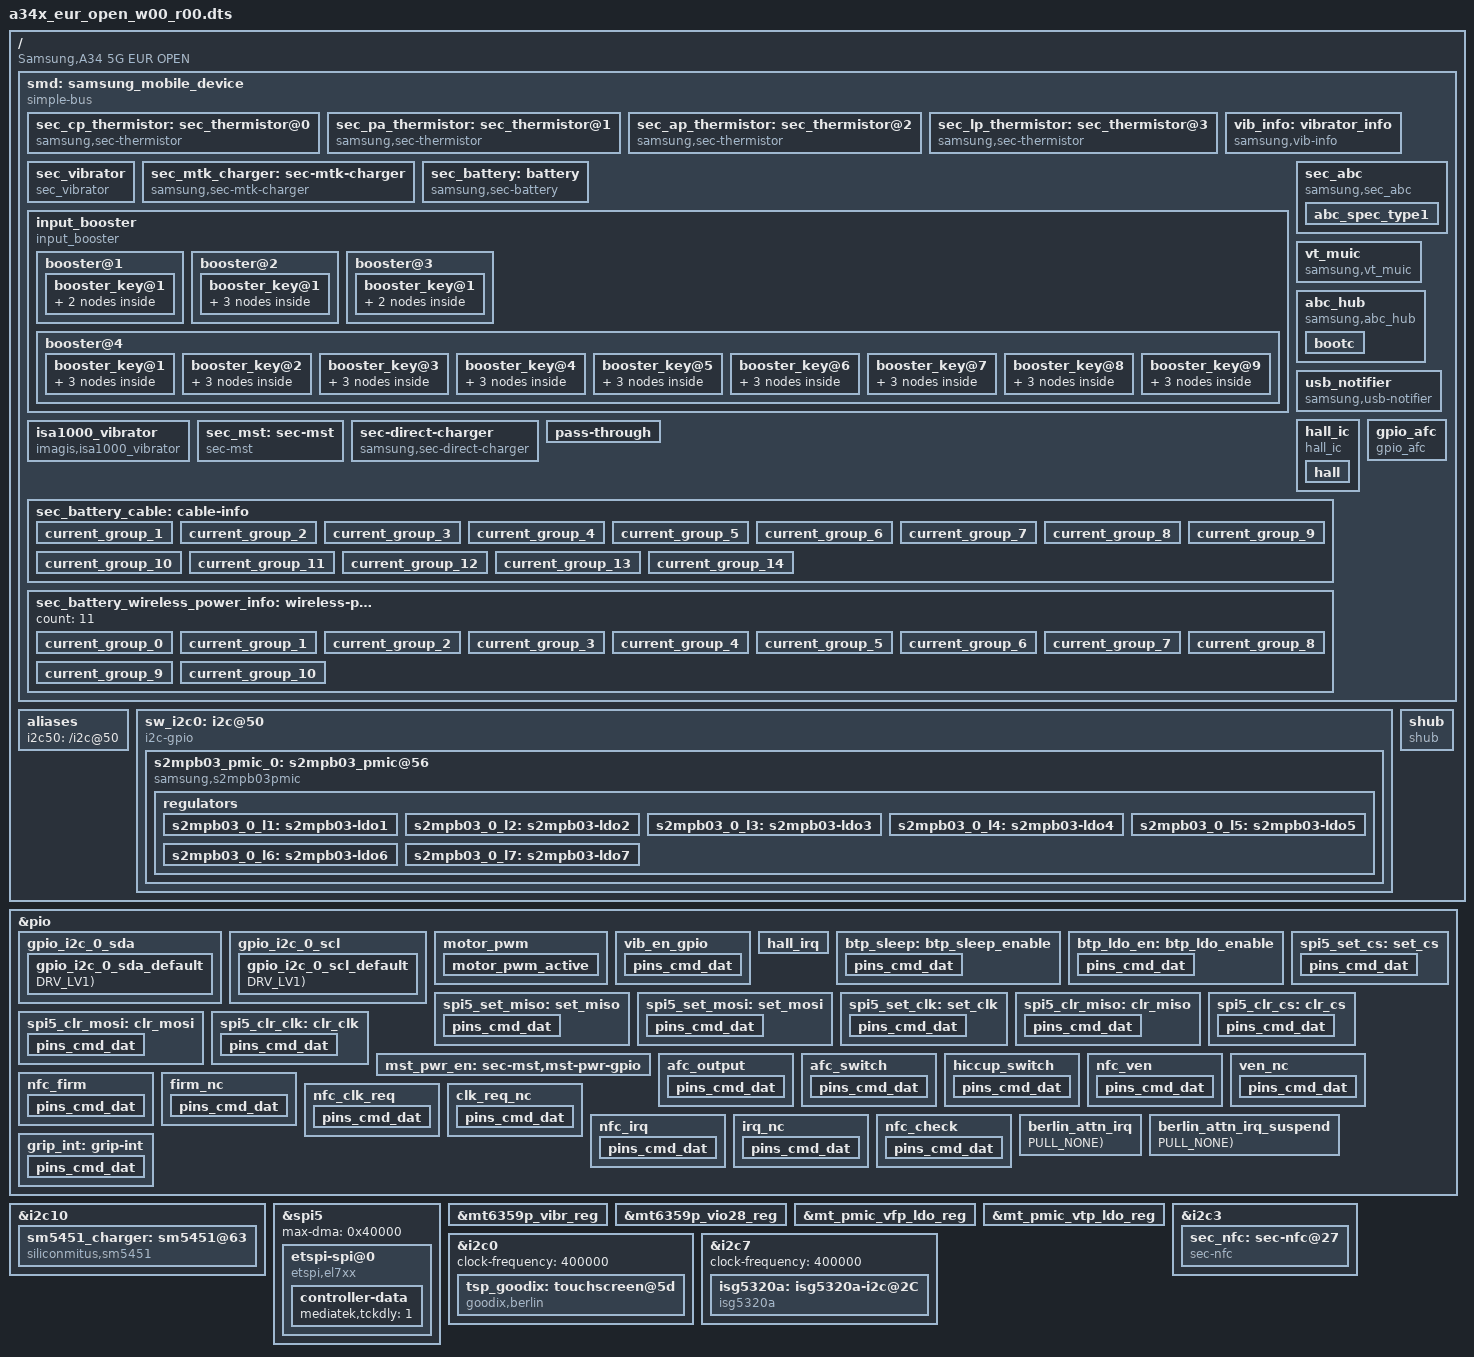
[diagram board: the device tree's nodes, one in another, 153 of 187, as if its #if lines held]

/*
 * Copyright (c) 2018 Samsung Electronics Co., Ltd.
 *              http://www.samsung.com
 *
 * This program is free software; you can redistribute it and/or modify
 * it under the terms of the GNU General Public License version 2 as
 * published by the Free Software Foundation.
*/

/dts-v1/;
/plugin/;
/ {
	fragment@smd {
		target-path = "/";
		__overlay__ {
			smd: samsung_mobile_device {
				compatible = "simple-bus";
			};
		};
	};
};

/* #include "../vibrator_vib_info.dtsi" */           /* From vibrator_vib_info.py */

&smd {
	vib_info: vibrator_info {
		status = "okay";
		compatible = "samsung,vib-info";
		functions = "INTENSITY", "HAPTIC_ENGINE";
#if 1
		samsung,intensities = <0 2000 4000 6000 8000 10000>;
#else
		samsung,intensities = <>;
#endif

#if 1
		samsung,haptic_intensities = <0 3000 4000 6000 8000 10000>;
#else
		samsung,haptic_intensities = <>;
#endif
	};
};

/* #include "../sec_vibrator.dtsi" */                /* From sec_vibrator.py */

&smd {
	sec_vibrator {
		status = "okay";
		compatible = "sec_vibrator";

		haptic,normal_ratio = <84>;
		haptic,high_temp_ref = <48>;
		haptic,high_temp_ratio = <71>;
	};
};


/* #include "../sec_mtk_charger.dtsi" */             /* From sec_mtk_charger.py */
#if 0
&${pogo_int_gpio_parent} {
	pogo_int_default: pogo_int_default {
		GPIO_CONFIG_PUD(${pogo_int_gpio}, FUNC_INPUT_WAKEUP, PULL_NONE);
	};
};
#endif

&smd {
	sec_mtk_charger: sec-mtk-charger {
#if 0
		pinctrl-names = "default";
		pinctrl-0 = <&pogo_int_default>;
		charger,pogo_int = <SEC_GPIO_REF(${pogo_int_gpio}) 0>; /* POGO_INT */
#endif
		compatible = "samsung,sec-mtk-charger";
		charger,vbus_min_charger_voltage = <4400000>;
		charger,vbus_normal_mivr_voltage = <4400000>;
		charger,gpio_chgenb = <&pio 184 0x0>;
		charger,max_icl = <3225>;
		charger,ib_fcc = <100>;
	};

	battery {
		battery,otg_name = "mtk-otg";
	};
};

/* /home/dpi/qb5_8814/workspace/P4_1716/android/kernel/kmodule/battery/suwon/charger/sec_mtk_charger/sec_mtk_charger.a34x.dtsi */

&smd {
	sec_mtk_charger: sec-mtk-charger {
		charger,gpio_chgenb = <&pio 27 0x0>;
		charger,mt6360_charger = <1>;
	};
};

/* #include "../nc.dtsi" */                          /* From nc.py */
#define LEGO_IS_USE_NC
#define LEGO_IS_USE(x, ...) !defined(LEGO_IS_USE_##x)

/* #include "../sec_pinctrl_wrapper.dtsi" */         /* From sec_pinctrl_wrapper.py */
#define PIN_FUNC_INPUT		input-enable
#define PIN_FUNC_INPUT_WAKEUP	input-enable
#define PIN_FUNC_OUTPUT		output-enable
#define PIN_FUNC_OUTPUT_HIGH		output-high
#define PIN_FUNC_OUTPUT_LOW		output-low

#define PIN_PULL_NONE	bias-disable
#define PIN_PULL_DOWN	bias-pull-down
#define PIN_PULL_UP	bias-pull-up
#define PIN_PULL_OPEN	bias-high-impedance

/*
 * MTK_DRIVE_2mA  2
 * MTK_DRIVE_4mA  4
 * MTK_DRIVE_6mA  6
 * MTK_DRIVE_8mA  8
 * MTK_DRIVE_10mA 10
 * MTK_DRIVE_12mA 12
 * MTK_DRIVE_14mA 14
 * MTK_DRIVE_16mA 16
 */

#define PIN_DRV_LV1	2
#define PIN_DRV_LV2	4
#define PIN_DRV_LV3	6
#define PIN_DRV_LV4	8
#define PIN_DRV_LV5	10
#define PIN_DRV_LV6	12
#define PIN_DRV_LV7	14
#define PIN_DRV_LV8	16

#define PIN_EXPAND(pin) #pin

#define SEC_GPIO(src, type, num)	PIN_EXPAND(gpio##num)
#define SEC_GPIO_REF(src, type, num)	&type num
#define SEC_GPIO_NUM(src, type, num)	num
#define SEC_GPIO_TYPE(src, type, num)	&type
#define SEC_GPIO_PHANDLE_ACTIVE(src, type, num)	SEC_GPIO_PHANDLE(type, num, active)
#define SEC_GPIO_PHANDLE_SLEEP(src, type, num)	SEC_GPIO_PHANDLE(type, num, sleep)
#define SEC_GPIO_PHANDLE(type, num, mode)	type##_##num##_##mode

#define MTK_PINMUX(gpio, func) (MTK_PIN_NO(gpio) | func)

#define GPIO_CONFIG(_src, _type, _num, _func)		\
	pins_cmd_dat{					\
		pinmux = <MTK_PINMUX(SEC_GPIO_NUM(_src, _type, _num), 0)>;	\
		PIN_ ##_func;		\
	}

#define GPIO_CONFIG_PUD(_src, _type, _num, _func, _pull)	\
	pins_cmd_dat{					\
		pinmux = <MTK_PINMUX(SEC_GPIO_NUM(_src, _type, _num), 0)>;	\
		PIN_ ##_pull;				\
		PIN_ ##_func;		\
	}

#define GPIO_CONFIG_PUD_DRV(_src, _type, _num, _func, _pull, _drv)	\
	pins_cmd_dat{					\
		pinmux = <MTK_PINMUX(SEC_GPIO_NUM(_src, _type, _num), 0)>;	\
		PIN_ ##_pull;				\
		PIN_ ##_func;		\
		drive-strength = <PIN_ ##_drv>;	\
	}

#define SEC_ADC(type, num) <&type num>
#define SEC_ADC_OPT(type, num) ,<&type num>
#define SEC_ADC_NUM(type, num) <num>

/* #include "../input_booster.dtsi" */               /* From input_booster.py */
/* Copyright (c) 2019, The Linux Foundation. All rights reserved.
 *
 * This program is free software; you can redistribute it and/or modify
 * it under the terms of the GNU General Public License version 2 and
 * only version 2 as published by the Free Software Foundation.
 *
 * This program is distributed in the hope that it will be useful,
 * but WITHOUT ANY WARRANTY; without even the implied warranty of
 * MERCHANTABILITY or FITNESS FOR A PARTICULAR PURPOSE.  See the
 * GNU General Public License for more details.
 */

&smd {
	input_booster {
		status = "okay";
		compatible = "input_booster";
		resValcount = "2";
		max_resource_count = "2";
		max_cluster_count = "3";
		#address-cells = <1>;
		#size-cells = <0>;

		/* Each Cpu Cluster Start Cpu */
		cpu_cluster_policy = "6,0";

		/* < CPU, DDR, SCHEDBOOST > */
		ib_release_values = "-1,16";

		/* Select Allowed Resource Index Group */
		allowed_resources = "0,1";

		booster@1 {
			booster,label = "Disable_Mode";
			booster,mode = "1";
			booster_key@1 {
				input_booster,label = "Touch_Disable";
				input_booster,type = <2>;	/* BOOSTER_DEVICE_TOUCH */
				/* Time table */
				input_booster,head_time = <0>;
				input_booster,tail_time = <0>;
				input_booster,resource {
					compatible = "resource";
					resource@1 {
						resource,label = "CPU";
						resource,id = "0";
						resource,value = <0 0>;
					};
				};
			};
		};

		booster@2 {
			booster,label = "Sip_Mode";
			booster,mode = "2";
			booster_key@1 {
				input_booster,label = "sip_touch";
				input_booster,type = <2>;	/* BOOSTER_DEVICE_TOUCH */
				/* Time table */
				input_booster,head_time = <120>;
				input_booster,tail_time = <0>;
				input_booster,resource {
					compatible = "resource";
					resource@1 {
						resource,label = "CPU";
						resource,id = "0";
						resource,value = <1140000 0>;
					};
					resource@2 {
						resource,label = "DDR";
						resource,id = "1";
						resource,value = <4266 4266>;
					};
				};
			};
		};

		booster@3 {
			booster,label = "Game_Mode";
			booster,mode = "3";
			booster_key@1 {
				input_booster,label = "GAME_MT";
				input_booster,type = <3>;	/* BOOSTER_DEVICE_MULTITOUCH */
				/* Time table */
				input_booster,head_time = <0>;
				input_booster,tail_time = <0>;
				input_booster,resource {
					compatible = "resource";
					resource@1 {
						resource,label = "CPU";
						resource,id = "0";
						resource,value = <0 0>;
					};
				};
			};
		};

		booster@4 {
			booster,label = "input_booster";
			booster,mode = "0";

			booster_key@1 {
				input_booster,label = "key";
				input_booster,type = <0>;	/* BOOSTER_DEVICE_KEY */

				/* Time table */
				input_booster,head_time = <200>;
				input_booster,tail_time = <0>;

				/* Resource Table Sequentially identified with index
				 * CPU's ID & Index : 0
				 * DDR's ID & Index : 1
				 * HMP's ID & Index : 2
				 * LPM's ID & Index : 3
				*/

				/* Input Booster Resource Frequency */
				inputbooster,resource {
					compatible = "resource";
					resource@1 {
						resource,label = "CPU";
						resource,id = "0";
						resource,value = <1540000 0>;
					};

					resource@2 {
						resource,label = "DDR";
						resource,id = "1";
						resource,value = <0 0>;
					};
				};
			};

			booster_key@2 {
				input_booster,label = "touchkey";
				input_booster,type = <1>;	/* BOOSTER_DEVICE_TOUCHKEY */

				/* Time table */
				input_booster,head_time = <1>;
				input_booster,tail_time = <300>;

				/* Input Booster Resource Frequency */
				inputbooster,resource {
					compatible = "resource";
					resource@1 {
						resource,label = "CPU";
						resource,id = "0";
						resource,value = <0 0>;
					};

					resource@2 {
						resource,label = "DDR";
						resource,id = "1";
						resource,value = <0 0>;
					};
				};
			};

			booster_key@3 {
				input_booster,label = "touch";
				input_booster,type = <2>;	/* BOOSTER_DEVICE_TOUCH */

				/* Time table */
				input_booster,head_time = <130>;
				input_booster,tail_time = <500>;

				/* Input Booster Resource Frequency */
				inputbooster,resource {
					compatible = "resource";
					resource@1 {
						resource,label = "CPU";
						resource,id = "0";
						resource,value = <1140000 1075200>;
					};

					resource@2 {
						resource,label = "DDR";
						resource,id = "1";
						resource,value = <4266 4266>;
					};
				};
			};

			booster_key@4 {
				input_booster,label = "multitouch";
				input_booster,type = <3>;	/* BOOSTER_DEVICE_MULTITOUCH */

				/* Time table */
				input_booster,head_time = <1000>;
				input_booster,tail_time = <500>;

				/* Input Booster Resource Frequency */
				inputbooster,resource {
					compatible = "resource";
					resource@1 {
						resource,label = "CPU";
						resource,id = "0";
						resource,value = <1140000 1075200>;
					};

					resource@2 {
						resource,label = "DDR";
						resource,id = "1";
						resource,value = <4266 4266>;
					};
				};
			};

			booster_key@5 {
				input_booster,label = "keyboard";
				input_booster,type = <4>;	/* BOOSTER_DEVICE_KEYBOARD */

				/* Time table */
				input_booster,head_time = <130>;
				input_booster,tail_time = <130>;

				/* Input Booster Resource Frequency */
				inputbooster,resource {
					compatible = "resource";
					resource@1 {
						resource,label = "CPU";
						resource,id = "0";
						resource,value = <1430000 1040000>;
					};

					resource@2 {
						resource,label = "DDR";
						resource,id = "1";
						resource,value = <4266 4266>;
					};
				};
			};

			booster_key@6 {
				input_booster,label = "MOUSE";
				input_booster,type = <5>;	/* BOOSTER_DEVICE_MOUSE */

				/* Time table */
				input_booster,head_time = <200>;
				input_booster,tail_time = <300>;

				/* Input Booster Resource Frequency */
				inputbooster,resource {
					compatible = "resource";
					resource@1 {
						resource,label = "CPU";
						resource,id = "0";
						resource,value = <1430000 1040000>;
					};

					resource@2 {
						resource,label = "DDR";
						resource,id = "1";
						resource,value = <4266 4266>;
					};
				};
			};

			booster_key@7 {
				input_booster,label = "mouse_wheel";
				input_booster,type = <6>;	/* BOOSTER_DEVICE_MOUSE */

				/* Time table */
				input_booster,head_time = <200>;
				input_booster,tail_time = <0>;

				/* Input Booster Resource Frequency */
				inputbooster,resource {
					compatible = "resource";
					resource@1 {
						resource,label = "CPU";
						resource,id = "0";
						resource,value = <1430000 0>;
					};

					resource@2 {
						resource,label = "DDR";
						resource,id = "1";
						resource,value = <4266 0>;
					};
				};
			};

			booster_key@8 {
				input_booster,label = "pen_hover";
				input_booster,type = <7>;	/* BOOSTER_DEVICE_MOUSE */

				/* Time table */
				input_booster,head_time = <200>;
				input_booster,tail_time = <300>;

				/* Input Booster Resource Frequency */
				inputbooster,resource {
					compatible = "resource";
					resource@1 {
						resource,label = "CPU";
						resource,id = "0";
						resource,value = <1430000 1040000>;
					};

					resource@2 {
						resource,label = "DDR";
						resource,id = "1";
						resource,value = <0 0>;
					};

				};
			};

			booster_key@9 {
				input_booster,label = "pen";
				input_booster,type = <8>;	/* BOOSTER_DEVICE_MOUSE */

				/* Time table */
				input_booster,head_time = <200>;
				input_booster,tail_time = <600>;

				/* Input Booster Resource Frequency */
				inputbooster,resource {
					compatible = "resource";
					resource@1 {
						resource,label = "CPU";
						resource,id = "0";
						resource,value = <1800000 1040000>;
					};

					resource@2 {
						resource,label = "DDR";
						resource,id = "1";
						resource,value = <4266 4266>;
					};
				};
			};
			/* If you need to add new key type, add it this position */
		};
	};
};

/* #include "../mtk_fuelgauge.dtsi" */               /* From mtk_fuelgauge.py */
&smd {
	battery {
		battery,fuelgauge_name = "mtk-fg-battery";
	};

	/* battery_prop.dtsi */
	bat_gm30: mtk_battery{
		compatible = "mediatek,bat_gm30";
		DIFFERENCE_FULLOCV_ITH = <(300)>;
	/*	Charging termination current*/
		SHUTDOWN_1_TIME = <(60)>;
	/*	If ui_soc shows 1% more than X minites, system will shutdown*/
		KEEP_100_PERCENT = <(1)>;
	/*	The ui_soc will keep 100% until SOC drop X percents after unplugged */
		R_FG_VALUE = <(5)>;
	/*	R_sense resistance*/
		EMBEDDED_SEL = <(0)>;
	/*	Configures whether using embedded battery or not*/
		PMIC_SHUTDOWN_CURRENT = <(20)>;
	/*	System shutdown current*/
		FG_METER_RESISTANCE = <(100)>;
	/*	The resistance of PCB*/
		CAR_TUNE_VALUE = <(99)>;
	/*	Tune value for current measurement*/
		PMIC_MIN_VOL = <(33500)>;
	/*	vboot voltage for gauge 0%*/
		POWERON_SYSTEM_IBOOT = <(500)>;
	/*	power on system iboot*/
		SHUTDOWN_GAUGE0 = <(0)>;
	/*	Shutdown condition2 switch*/
		SHUTDOWN_GAUGE0_VOLTAGE = <(34000)>;
	/*	shutdown gauge 0% voltage*/
		TEMPERATURE_T0 = <(50)>;
	/*	Battery temperature T0*/
		TEMPERATURE_T1 = <(25)>;
	/*	Battery temperature T1*/
		TEMPERATURE_T2 = <(10)>;
	/*	Battery temperature T2*/
		TEMPERATURE_T3 = <(0)>;
	/*	Battery temperature T3*/
		TEMPERATURE_T4 = <(-10)>;
	/*	Battery temperature T4*/
		TEMPERATURE_T5 = <(-20)>;
	/*	Battery temperature T5*/
		g_FG_PSEUDO100_T0 = <(93)>;
	/*	Pseudo 100% percentage at T0*/
		g_FG_PSEUDO100_T1 = <(93)>;
	/*	Pseudo 100% percentage at T1*/
		g_FG_PSEUDO100_T2 = <(93)>;
	/*	Pseudo 100% percentage at T2*/
		g_FG_PSEUDO100_T3 = <(93)>;
	/*	Pseudo 100% percentage at T3*/
		g_FG_PSEUDO100_T4 = <(93)>;
	/*	Pseudo 100% percentage at T4*/
		g_FG_PSEUDO100_T5 = <(93)>;
	/*	Pseudo 100% percentage at T4*/
		Q_MAX_SYS_VOLTAGE_BAT0 = <(3350)>;
	/*	Pseudo1 for hide percentage*/
		Q_MAX_SYS_VOLTAGE_BAT1 = <(3350)>;
	/*	Pseudo1 for hide percentage*/
		Q_MAX_SYS_VOLTAGE_BAT2 = <(3350)>;
	/*	Pseudo1 for hide percentage*/
		Q_MAX_SYS_VOLTAGE_BAT3 = <(3350)>;
	/*	Pseudo1 for hide percentage*/
		COM_FG_METER_RESISTANCE = <(100)>;
	/*	compensate The resistance of PCB*/
		COM_R_FG_VALUE = <(0)>;
	/*	compensate R_sense resistance*/
		enable_tmp_intr_suspend = <(0)>;
	/* Enable update temp when suspend */
		ACTIVE_TABLE = <(6)>;
	/* Table numbers per battery*/
		MULTI_TEMP_GAUGE0 = <(1)>;
	/* Multi gauge0 enable*/
		HWOCV_OLDOCV_DIFF = <(100)>;
	/* Diff of HWOCV and SWOCV*/

	/* battery_table.dtsi*/
	battery0_profile_t0_num = <100>;
	battery0_profile_t0_col = <3>;
	battery0_profile_t0 =
	<
	0       43520   850
	486     43380   866
	972     43251   875
	1458    43130   897
	1944    43004   875
	2430    42881   875
	2916    42760   875
	3402    42644   875
	3888    42530   900
	4375    42407   875
	4861    42293   881
	5347    42178   900
	5833    42054   875
	6319    41941   897
	6805    41820   875
	7291    41714   875
	7777    41601   900
	8263    41485   875
	8749    41372   875
	9235    41267   897
	9721    41155   875
	10207   41051   875
	10693   40945   875
	11179   40837   884
	11665   40739   875
	12152   40642   900
	12638   40542   894
	13124   40446   919
	13610   40350   900
	14096   40253   900
	14582   40162   919
	15068   40070   925
	15554   39979   925
	16040   39898   941
	16526   39817   950
	17012   39736   950
	17498   39655   962
	17984   39573   975
	18470   39492   975
	18956   39411   1000
	19442   39329   1025
	19928   39210   975
	20415   39078   938
	20901   38949   878
	21387   38849   875
	21873   38773   850
	22359   38699   850
	22845   38635   850
	23331   38580   850
	23817   38521   850
	24303   38472   850
	24789   38423   850
	25275   38374   875
	25761   38326   850
	26247   38285   869
	26733   38239   850
	27219   38200   875
	27705   38157   866
	28192   38115   868
	28678   38082   872
	29164   38050   875
	29650   38007   853
	30136   37975   875
	30622   37952   900
	31108   37919   900
	31594   37887   900
	32080   37865   907
	32566   37841   925
	33052   37810   925
	33538   37765   900
	34024   37684   861
	34510   37614   865
	34996   37550   851
	35482   37511   859
	35968   37465   857
	36455   37424   853
	36941   37374   850
	37427   37337   875
	37913   37304   875
	38399   37272   875
	38885   37230   875
	39371   37185   900
	39857   37120   875
	40343   37063   875
	40829   37004   888
	41315   36942   879
	41801   36861   881
	42287   36806   860
	42773   36790   875
	43259   36780   891
	43745   36767   907
	44232   36751   948
	44718   36719   976
	45204   36643   1018
	45690   36372   937
	46176   35944   969
	46662   35387   1000
	47148   34581   1041
	47634   33318   1181
	48120   30130   10325
	>;
	battery0_profile_t1_num = <100>;
	battery0_profile_t1_col = <3>;
	battery0_profile_t1 =
	<
	0       43320   1450
	486     43164   1450
	972     43033   1475
	1458    42911   1475
	1944    42789   1475
	2430    42671   1475
	2916    42550   1456
	3402    42434   1475
	3888    42320   1475
	4375    42197   1440
	4861    42083   1431
	5347    41968   1428
	5833    41854   1437
	6319    41741   1428
	6805    41628   1431
	7291    41514   1425
	7777    41401   1425
	8263    41295   1425
	8749    41184   1407
	9235    41078   1403
	9721    40975   1412
	10207   40871   1425
	10693   40765   1425
	11179   40667   1416
	11665   40569   1425
	12152   40475   1450
	12638   40382   1450
	13124   40277   1450
	13610   40190   1450
	14096   40093   1447
	14582   40002   1444
	15068   39920   1460
	15554   39839   1450
	16040   39758   1450
	16526   39687   1500
	17012   39606   1500
	17498   39525   1500
	17984   39443   1504
	18470   39354   1525
	18956   39243   1490
	19442   39109   1425
	19928   38980   1344
	20415   38875   1319
	20901   38787   1300
	21387   38719   1313
	21873   38654   1300
	22359   38589   1300
	22845   38535   1290
	23331   38480   1300
	23817   38431   1291
	24303   38384   1300
	24789   38343   1300
	25275   38294   1300
	25761   38257   1303
	26247   38217   1325
	26733   38182   1309
	27219   38140   1325
	27705   38107   1341
	28192   38075   1332
	28678   38042   1350
	29164   38010   1350
	29650   37987   1375
	30136   37955   1375
	30622   37926   1375
	31108   37900   1376
	31594   37877   1384
	32080   37855   1400
	32566   37822   1378
	33052   37790   1375
	33538   37747   1375
	34024   37707   1356
	34510   37672   1360
	34996   37630   1351
	35482   37591   1359
	35968   37552   1350
	36455   37512   1372
	36941   37480   1375
	37427   37447   1375
	37913   37414   1394
	38399   37368   1385
	38885   37310   1376
	39371   37248   1393
	39857   37192   1400
	40343   37134   1423
	40829   37063   1412
	41315   36975   1425
	41801   36935   1425
	42287   36920   1460
	42773   36910   1475
	43259   36894   1500
	43745   36867   1514
	44232   36833   1573
	44718   36727   1613
	45204   36421   1607
	45690   35937   1688
	46176   35299   1804
	46662   34415   1951
	47148   32710   2488
	47634   30570   11550
	48120   30570   11550
	>;
	battery0_profile_t2_num = <100>;
	battery0_profile_t2_col = <3>;
	battery0_profile_t2 =
	<
	0       43000   3200
	486     42808   3293
	972     42661   3412
	1458    42531   3472
	1944    42404   3476
	2430    42281   3478
	2916    42160   3481
	3402    42044   3484
	3888    41930   3475
	4375    41817   3485
	4861    41695   3456
	5347    41579   3431
	5833    41474   3450
	6319    41361   3425
	6805    41255   3425
	7291    41144   3425
	7777    41041   3425
	8263    40931   3416
	8749    40834   3407
	9235    40737   3425
	9721    40640   3425
	10207   40541   3444
	10693   40435   3419
	11179   40337   3425
	11665   40229   3375
	12152   40138   3391
	12638   40047   3381
	13124   39957   3378
	13610   39875   3400
	14096   39794   3375
	14582   39712   3375
	15068   39640   3415
	15554   39559   3425
	16040   39472   3409
	16526   39382   3425
	17012   39269   3381
	17498   39146   3350
	17984   39008   3268
	18470   38894   3225
	18956   38801   3200
	19442   38720   3200
	19928   38655   3200
	20415   38590   3200
	20901   38534   3222
	21387   38479   3225
	21873   38426   3250
	22359   38377   3250
	22845   38329   3275
	23331   38280   3275
	23817   38241   3300
	24303   38202   3325
	24789   38162   3347
	25275   38130   3363
	25761   38087   3378
	26247   38055   3400
	26733   38022   3425
	27219   37990   3425
	27705   37967   3466
	28192   37935   3500
	28678   37911   3500
	29164   37885   3525
	29650   37859   3528
	30136   37842   3569
	30622   37822   3600
	31108   37800   3601
	31594   37784   3641
	32080   37757   3657
	32566   37732   3697
	33052   37700   3700
	33538   37667   3728
	34024   37627   3750
	34510   37592   3795
	34996   37559   3850
	35482   37517   3866
	35968   37482   3932
	36455   37434   3972
	36941   37374   4026
	37427   37314   4104
	37913   37249   4144
	38399   37190   4235
	38885   37119   4325
	39371   37028   4398
	39857   36965   4501
	40343   36932   4666
	40829   36905   4816
	41315   36877   5048
	41801   36845   5310
	42287   36790   5653
	42773   36689   6028
	43259   36466   6433
	43745   36033   6914
	44232   35419   7720
	44718   34544   8974
	45204   33115   11297
	45690   30950   12525
	46176   30950   12525
	46662   30950   12525
	47148   30950   12525
	47634   30950   12525
	48120   30950   12525
	>;
	battery0_profile_t3_num = <100>;
	battery0_profile_t3_col = <3>;
	battery0_profile_t3 =
	<
	0       42520   5950
	486     42262   6183
	972     42098   6518
	1458    41961   6640
	1944    41824   6714
	2430    41701   6753
	2916    41580   6775
	3402    41464   6816
	3888    41350   6825
	4375    41237   6840
	4861    41123   6825
	5347    41017   6847
	5833    40909   6825
	6319    40812   6847
	6805    40715   6844
	7291    40604   6825
	7777    40501   6825
	8263    40385   6784
	8749    40274   6782
	9235    40177   6800
	9721    40080   6800
	10207   39984   6778
	10693   39903   6781
	11179   39821   6784
	11665   39739   6800
	12152   39658   6791
	12638   39587   6825
	13124   39497   6803
	13610   39410   6813
	14096   39312   6797
	14582   39196   6756
	15068   39069   6680
	15554   38949   6625
	16040   38836   6584
	16526   38747   6569
	17012   38666   6550
	17498   38600   6575
	17984   38536   6579
	18470   38479   6600
	18956   38418   6635
	19442   38370   6675
	19928   38321   6691
	20415   38275   6706
	20901   38234   6725
	21387   38194   6750
	21873   38156   6775
	22359   38115   6794
	22845   38082   6835
	23331   38050   6850
	23817   38018   6891
	24303   37984   6907
	24789   37952   6925
	25275   37930   6975
	25761   37909   7003
	26247   37892   7044
	26733   37876   7084
	27219   37860   7125
	27705   37843   7183
	28192   37827   7214
	28678   37811   7295
	29164   37795   7351
	29650   37777   7407
	30136   37752   7488
	30622   37722   7544
	31108   37689   7626
	31594   37657   7723
	32080   37622   7813
	32566   37582   7939
	33052   37540   8076
	33538   37495   8238
	34024   37437   8422
	34510   37374   8610
	34996   37309   8853
	35482   37238   9080
	35968   37170   9352
	36455   37096   9676
	36941   37004   10017
	37427   36935   10393
	37913   36894   10858
	38399   36862   11389
	38885   36830   11982
	39371   36791   12670
	39857   36740   13453
	40343   36656   14301
	40829   36424   15025
	41315   35986   15823
	41801   35349   16953
	42287   34442   18475
	42773   33430   18575
	43259   33430   18575
	43745   33430   18575
	44232   33430   18575
	44718   33430   18575
	45204   33430   18575
	45690   33430   18575
	46176   33430   18575
	46662   33430   18575
	47148   33430   18575
	47634   33430   18575
	48120   33430   18575
	>;
	battery0_profile_t4_num = <100>;
	battery0_profile_t4_col = <3>;
	battery0_profile_t4 =
	<
	0       42010   11330
	486     41738   11604
	972     41429   12066
	1458    41171   12469
	1944    40989   12751
	2430    40838   12878
	2916    40700   12919
	3402    40570   12916
	3888    40440   12875
	4375    40311   12819
	4861    40181   12744
	5347    40058   12703
	5833    39949   12675
	6319    39842   12650
	6805    39745   12650
	7291    39648   12616
	7777    39541   12526
	8263    39441   12509
	8749    39332   12437
	9235    39227   12378
	9721    39115   12312
	10207   39013   12272
	10693   38923   12250
	11179   38841   12216
	11665   38759   12200
	12152   38694   12184
	12638   38622   12175
	13124   38565   12175
	13610   38510   12200
	14096   38456   12178
	14582   38407   12200
	15068   38358   12210
	15554   38310   12225
	16040   38261   12241
	16526   38215   12256
	17012   38174   12297
	17498   38140   12325
	17984   38097   12329
	18470   38065   12350
	18956   38032   12375
	19442   38010   12450
	19928   37977   12475
	20415   37955   12506
	20901   37931   12568
	21387   37905   12626
	21873   37874   12675
	22359   37855   12770
	22845   37832   12819
	23331   37800   12900
	23817   37778   13031
	24303   37744   13121
	24789   37712   13242
	25275   37670   13327
	25761   37626   13460
	26247   37577   13639
	26733   37535   13728
	27219   37480   13875
	27705   37420   14031
	28192   37359   14202
	28678   37294   14386
	29164   37230   14552
	29650   37155   14720
	30136   37090   14944
	30622   37028   15148
	31108   36979   15354
	31594   36947   15613
	32080   36905   15847
	32566   36863   16130
	33052   36790   16376
	33538   36673   16644
	34024   36429   16891
	34510   36018   17215
	34996   35399   17761
	35482   34431   18699
	35968   32802   17069
	36455   31080   12750
	36941   31080   12750
	37427   31080   12750
	37913   31080   12750
	38399   31080   12750
	38885   31080   12750
	39371   31080   12750
	39857   31080   12750
	40343   31080   12750
	40829   31080   12750
	41315   31080   12750
	41801   31080   12750
	42287   31080   12750
	42773   31080   12750
	43259   31080   12750
	43745   31080   12750
	44232   31080   12750
	44718   31080   12750
	45204   31080   12750
	45690   31080   12750
	46176   31080   12750
	46662   31080   12750
	47148   31080   12750
	47634   31080   12750
	48120   31080   12750
	>;
	battery0_profile_t5_num = <100>;
	battery0_profile_t5_col = <3>;
	battery0_profile_t5 =
	<
	0       40920   10780
	483     40610   11233
	967     40337   12231
	1450    40095   12975
	1933    39872   13686
	2417    39674   14479
	2900    39510   15208
	3383    39378   15667
	3867    39258   15931
	4350    39150   16075
	4833    39042   16178
	5317    38929   16164
	5800    38830   16208
	6283    38733   16319
	6767    38652   16378
	7250    38573   16404
	7733    38509   16464
	8217    38444   16519
	8700    38390   16625
	9183    38335   16666
	9667    38292   16706
	10150   38244   16725
	10633   38200   16750
	11117   38158   16752
	11600   38126   16810
	12083   38087   16833
	12567   38052   16965
	13050   38019   16990
	13533   37987   17100
	14017   37955   17176
	14500   37919   17218
	14983   37880   17323
	15467   37838   17390
	15950   37794   17510
	16433   37738   17550
	16917   37683   17714
	17400   37629   17828
	17883   37564   17981
	18367   37500   18070
	18850   37427   18222
	19333   37361   18385
	19817   37286   18407
	20300   37222   18563
	20783   37158   18764
	21267   37093   18919
	21750   37039   19080
	22233   36974   19247
	22717   36910   19451
	23200   36824   19655
	23683   36692   19921
	24167   36470   20134
	24650   36118   20420
	25133   35546   20803
	25617   34662   21167
	26100   33270   18200
	26583   32530   16450
	27067   32530   16450
	27550   32530   16450
	28033   32530   16450
	28517   32530   16450
	29000   32530   16450
	29483   32530   16450
	29967   32530   16450
	30450   32530   16450
	30933   32530   16450
	31417   32530   16450
	31900   32530   16450
	32383   32530   16450
	32867   32530   16450
	33350   32530   16450
	33833   32530   16450
	34317   32530   16450
	34800   32530   16450
	35283   32530   16450
	35767   32530   16450
	36250   32530   16450
	36733   32530   16450
	37217   32530   16450
	37700   32530   16450
	38183   32530   16450
	38667   32530   16450
	39150   32530   16450
	39633   32530   16450
	40117   32530   16450
	40600   32530   16450
	41083   32530   16450
	41567   32530   16450
	42050   32530   16450
	42533   32530   16450
	43017   32530   16450
	43500   32530   16450
	43983   32530   16450
	44467   32530   16450
	44950   32530   16450
	45433   32530   16450
	45917   32530   16450
	46400   32530   16450
	46883   32530   16450
	47367   32530   16450
	47850   32530   16450
	>;

	/* battery_prop_dim2_ext.dtsi */
	/*vboot voltage for gauge 0%*/
	g_PMIC_MIN_VOL_row = <4>;
	g_PMIC_MIN_VOL_col = <10>;
	g_PMIC_MIN_VOL =
	<
		32700  32700  32700  32700
		32700  32700  32700  32700
		32700  32700  32700  32700
		32200  32200  32200  32200
		31000  31000  31000  31000
		31500  31500  31500  31500
		31000  31000  31000  31000
		31000  31000  31000  31000
		31000  31000  31000  31000
		31000  31000  31000  31200
	>;
	/*boot_up current for gauge 0%*/
	g_PON_SYS_IBOOT_row = <4>;
	g_PON_SYS_IBOOT_col = <10>;
	g_PON_SYS_IBOOT =
	<
		5000  5000  5000  5000
		5000  5000  5000  5000
		5000  5000  5000  5000
		5000  5000  5000  5000
		5000  5000  5000  5000
		5000  5000  5000  5000
		5000  5000  5000  5000
		5000  5000  5000  5000
		5000  5000  5000  5000
		5000  5000  5000  5000
	>;
	/*Pseudo1 hide percentage*/
	g_QMAX_SYS_VOL_row = <4>;
	g_QMAX_SYS_VOL_col = <10>;
	g_QMAX_SYS_VOL =
	<
		33600  33600  33600  33600
		33600  33600  33600  33600
		33600  33600  33600  33600
		33600  33600  33600  33600
		33600  33600  33600  33600
		32500  32500  32500  32500
		32800  32800  32800  32800
		32800  32800  32800  32800
		32800  32800  32800  32800
		32800  32800  32800  32800
	>;
	/*Pseudo100 percentage setting*/
	g_FG_PSEUDO100_row = <4>;
	g_FG_PSEUDO100_col = <10>;
	g_FG_PSEUDO100 =
	<
		91  100  100  100
		91  100  100  100
		91  100  100  100
		91  100  100  100
		91  100  100  100
		91  100  100  100
		100  100  100  100
		100  100  100  100
		100  100  100  100
		100  100  100  100
	>;

	};
};

/* /home/dpi/qb5_8814/workspace/P4_1716/android/kernel/kmodule/battery/suwon/fuelgauge/mtk_fuelgauge/mtk_fuelgauge.a34x.dtsi */
&smd {
	battery {
		battery,fuelgauge_name = "mtk-fg-battery";
	};

	/delete-node/ mtk_battery;

};

/* #include "../abc_spec_manager_type1.dtsi" */      /* From abc_spec_manager_type1.py */
&smd {
	sec_abc {
		compatible = "samsung,sec_abc";
		status = "okay";
		abc_spec_type1 {
			module_list = "gpu", "gpu_qc", "gpu_qc", "camera", "camera", "vib", "tsp", "tsp_sub", "mm", "camera", "camera", "camera", "camera", "camera", "camera", "camera", "camera", "camera", "gpu";
			name_list = "gpu_fault", "gpu_fault", "gpu_page_fault", "mipi_overflow", "i2c_fail", "int_gnd_short", "tsp_int_fault", "tsp_int_fault", "venus_hung", "mipi_error_rw1", "mipi_error_rs1", "mipi_error_rt1", "mipi_error_fw1", "mipi_error_rt2", "mipi_error_uw1", "mipi_error_rm1", "mipi_error_rb1", "mipi_error_fs1", "gpu_job_timeout";
#ifndef CONFIG_SEC_FACTORY
			threshold_cnt = <20>, <2>, <20>, <1>, <1>, <25>, <2>, <2>, <10>, <1>, <1>, <1>, <1>, <1>, <1>, <1>, <1>, <1>, <1>;
			threshold_time = <1200>, <1200>, <1200>, <0>, <0>, <5>, <5>, <5>, <3>, <0>, <0>, <0>, <0>, <0>, <0>, <0>, <0>, <0>, <0>;
#else
			threshold_cnt = <20>, <2>, <20>, <4>, <4>, <25>, <2>, <2>, <10>, <4>, <4>, <4>, <4>, <4>, <4>, <4>, <4>, <4>, <1>;
			threshold_time = <1200>, <1200>, <1200>, <120>, <120>, <5>, <5>, <5>, <3>, <120>, <120>, <120>, <120>, <120>, <120>, <120>, <120>, <120>, <0>;
#endif
		};
	};
};

/* #include "../ap_mtk_mt6877.dtsi" */               /* From ap_mtk_mt6877.py */
#include <dt-bindings/clock/mt6877-clk.h>
/* /home/dpi/qb5_8814/workspace/P4_1716/android/kernel/kmodule/ap/mtk/mt6877/ap_mtk_mt6877.a34x_eur.00.dtsi */
#include "../../mediatek/k6877ttv1_64_titan_black_tiger/board_00.dts"
#include "../../mediatek/k6877ttv1_64_titan_black_tiger/gpio_00.dtsi"

/* #include "../vt_muic.dtsi" */                     /* From vt_muic.py */
#if 0
&${jtag_usb_id_parent} {
	jtag_usb_id: jtag_usb_id {
		GPIO_CONFIG_PUD_DRV(${jtag_usb_id_gpio}, FUNC_INPUT_WAKEUP, PULL_NONE, DRV_LV1);
	};
};
#endif

&smd {
	vt_muic {
		compatible = "samsung,vt_muic";
		status = "okay";
#if 0
		pinctrl-names = "default";
		pinctrl-0 = <&jtag_usb_id>;
		vt_muic,usb_id = <SEC_GPIO_REF(${jtag_usb_id_gpio}) 0>;
#endif
#if 1
		use_battery_notifier_callback;
#endif
#if 1
		use_manager_notifier_callback;
#endif
	};
};


/* #include "../abc_common.dtsi" */                  /* From abc_common.py */
&smd {
	abc_hub {
		compatible = "samsung,abc_hub";
		status = "okay";
		bootc {
			bootc,time_spec_user = <100000>; /* user binary user build */
			bootc,time_spec_eng = <150000>; /* user binary eng build */
			bootc,time_spec_fac = <100000>; /* factory binary */
		};
	};
};

/* #include "../usb_notifier.dtsi" */                /* From usb_notifier.py */

&smd {
	usb_notifier {
		compatible = "samsung,usb-notifier";
		status = "okay";
#if 0
		support_reverse_bypass_en;
#endif
	};
};


/* #include "../i2c-gpio.dtsi" */                    /* From i2c-gpio.py */
&pio {
       gpio_i2c_0_sda {
               gpio_i2c_0_sda_default: gpio_i2c_0_sda_default {
                       GPIO_CONFIG_PUD_DRV(AP,pio,163, FUNC_INPUT, PULL_NONE, DRV_LV1);
               };
       };
};

&pio {
       gpio_i2c_0_scl {
               gpio_i2c_0_scl_default: gpio_i2c_0_scl_default {
                       GPIO_CONFIG_PUD_DRV(AP,pio,162, FUNC_INPUT, PULL_NONE, DRV_LV1);
               };
       };
};

/ {
	fragment@model {
		target-path = "/";
	        __overlay__ {
			aliases {
				  i2c50 = "/i2c@50";
			};
			/* Software I2C */
			sw_i2c0: i2c@50 {
				cell-index = <50>;
				compatible = "i2c-gpio";
				gpios = <
					SEC_GPIO_REF(AP,pio,163) 0 /* SDA */
					SEC_GPIO_REF(AP,pio,162) 0 /* SCL */
					>;
				#i2c-gpio,delay-us = <2>;
				#address-cells = <1>;
				#size-cells = <0>;

				pinctrl-names = "default";
				pinctrl-0 = <
					&gpio_i2c_0_sda_default
					&gpio_i2c_0_scl_default
					>;

				status = "disabled";
			};
		};
	};
};


/* #include "../sm5451_charger.dtsi" */              /* From sm5451_charger.py */
&i2c10 {
	status = "okay";

	sm5451_charger: sm5451@63 {
		compatible = "siliconmitus,sm5451";
		reg = <0x63>;
	};
};

/* /home/dpi/qb5_8814/workspace/P4_1716/android/kernel/kmodule/battery/suwon/charger/sm5451/sm5451_charger.a34x.dtsi */
&sm5451_charger {
	sm5451,freq_byp = <0x1>; /* 375kHz */
	sm5451,freq = <2>; /* 500kHz */
	sm5451,r_ttl = <520000>;
	sm5451,topoff = <380>;
	sm5451,en_vbatreg = <1>;
};

/* #include "../sec_thermistor.dtsi" */              /* From sec_thermistor.py */
/ {
	fragment@smd {
		target-path = "/";
		__overlay__ {
			samsung_mobile_device {
				sec_cp_thermistor: sec_thermistor@0 {
					compatible = "samsung,sec-thermistor";
					status = "okay";
					thermistor_name = "sec-cp-thermistor";
					id = <0>;

					io-channels = SEC_ADC(auxadc,2);
					io-channel-names = "cp_therm";
					io-channel-ranges;
				};
			};
		};
	};
};

/* #include "../sec_thermistor-1.dtsi" */            /* From sec_thermistor.py */
/ {
	fragment@smd {
		target-path = "/";
		__overlay__ {
			samsung_mobile_device {
				sec_pa_thermistor: sec_thermistor@1 {
					compatible = "samsung,sec-thermistor";
					status = "okay";
					thermistor_name = "sec-pa-thermistor";
					id = <1>;

					io-channels = SEC_ADC(auxadc,1);
					io-channel-names = "pa_therm";
					io-channel-ranges;
				};
			};
		};
	};
};

/* #include "../sec_thermistor-2.dtsi" */            /* From sec_thermistor.py */
/ {
	fragment@smd {
		target-path = "/";
		__overlay__ {
			samsung_mobile_device {
				sec_ap_thermistor: sec_thermistor@2 {
					compatible = "samsung,sec-thermistor";
					status = "okay";
					thermistor_name = "sec-ap-thermistor";
					id = <2>;

					io-channels = SEC_ADC(auxadc,0);
					io-channel-names = "ap_therm";
					io-channel-ranges;
				};
			};
		};
	};
};

/* #include "../sec_thermistor-3.dtsi" */            /* From sec_thermistor.py */
/ {
	fragment@smd {
		target-path = "/";
		__overlay__ {
			samsung_mobile_device {
				sec_lp_thermistor: sec_thermistor@3 {
					compatible = "samsung,sec-thermistor";
					status = "okay";
					thermistor_name = "sec-lp-thermistor";
					id = <3>;

					io-channels = SEC_ADC(auxadc,4);
					io-channel-names = "lp_therm";
					io-channel-ranges;
				};
			};
		};
	};
};

/* /home/dpi/qb5_8814/workspace/P4_1716/android/kernel/kmodule/sec_pm/sec_thermistor/dts/sec_thermistor_mtk.a34x.dtsi */
&sec_ap_thermistor {
	adc_array = <84 102 124 149 174 210 240 287 356 411
				507 605 733 875 1061 1285 1519 1785 2086 2408
				2741 2982 3366>;

	temp_array = <900 850 800 750 700 650 600 550 500 450
				400 350 300 250 200 150 100 50 0 (-50)
				(-100) (-150) (-200)>;
};

&sec_pa_thermistor {
	adc_array = <332 397 468 555 634 752 879 977 1136 1316
				1544 1766 2019 2276 2567 2870 3141 3410 3660 3892
				4026 4095 4095>;

	temp_array = <900 850 800 750 700 650 600 550 500 450
				400 350 300 250 200 150 100 50 0 (-50)
				(-100) (-150) (-200)>;
};

&sec_cp_thermistor {
	adc_array = <335 399 469 557 636 754 846 977 1138 1317
				1548 1764 2009 2277 2436 2770 3029 3408 3665 3895
				4026 4095 4095>;

	temp_array = <900 850 800 750 700 650 600 550 500 450
				400 350 300 250 200 150 100 50 0 (-50)
				(-100) (-150) (-200)>;
};

&sec_lp_thermistor {
	adc_array = <324 390 463 548 592 701 802 914 1075 1225
				1450 1662 1908 2155 2451 2754 3026 3272 3533 3776
				3988 4095 4095>;

	temp_array = <900 850 800 750 700 650 600 550 500 450
				400 350 300 250 200 150 100 50 0 (-50)
				(-100) (-150) (-200)>;
};

/* #include "../isa1000_vibrator.dtsi" */            /* From isa1000_vibrator.py */
#define EXPAND(str) #str

&pio {
	/* add pinctrl for motor  */
	motor_pwm {
		motor_pwm_active: motor_pwm_active {
			pinmux = <PINMUX_GPIO0__FUNC_PWM_0>;
			bias-disable;
			output-low;
		  };
	};
};

&pio {
	vib_en_gpio: vib_en_gpio {
		pins_cmd_dat {
			pinmux = <MTK_PINMUX(SEC_GPIO_NUM(AP,pio,195), 0)>;
			slew-rate = <1>;
			bias-disable;
			output-low;
		};
	};
};


&smd {
	isa1000_vibrator {
		status = "okay";
		compatible = "imagis,isa1000_vibrator";
		isa1000,duty_ratio = <84>;
		isa1000,gpio_en = <SEC_GPIO_REF(AP,pio,195) 0>;
		isa1000,motor_type = EXPAND(LINEAR_1040);

#if 1
		/* for multi-frequency */
		isa1000,multi_frequency = <1>;
#endif
		/* frequency       alert low  mid  high  0  press release (multi_freq)*/
		isa1000,frequency = <2050>;

		pinctrl-names = "default";
		pinctrl-0 = <&motor_pwm_active &vib_en_gpio>;
	/*	#pwms = <&mtk_pwm 0 1000000>; */

		samsung,steps = <6>;
		samsung,intensities = <0 3000 4000 6000 8000 10000>;
		samsung,haptic_intensities = <0 2000 4000 6000 8000 10000>;
	};
};

/* #include "../hall_ic.dtsi" */                     /* From hall_ic.py */
/*
 * Hall ic device tree source
 *
 * Copyright (c) 2017 Samsung Electronics Co., Ltd.
 *		http://www.samsung.com
 *
 * This program is free software; you can redistribute it and/or modify
 * it under the terms of the GNU General Public License version 2 as
 * published by the Free Software Foundation.
 */

&smd {
	hall_ic: hall_ic {
		status = "okay";
		compatible = "hall_ic";
		pinctrl-names = "default";
		pinctrl-0 = <
#if 1
		&hall_irq
#endif
#if 0
		&certify_hall_irq
#endif
#if 0
		&hall_wacom_irq
#endif
		>;
#if 1
		hall_ic,debounce-interval = <50>;
#endif
#if 1
		hall: hall {
			name = "hall";
			event = <0x15>;
			gpios = <SEC_GPIO_REF(AP,pio,6) 1>;
			flags = <0x01>;
		};
#endif
#if 0
		certify_hall: certify_hall {
			name = "certify_hall";
			event = <0x1b>;
			gpios = <SEC_GPIO_REF(${certify_hall_gpio}) 1>;
		};
#endif
#if 0
		hall_wacom: hall_wacom {
			name = "hall_wacom";
			event = <0x1e>;
			gpios = <SEC_GPIO_REF(${wacom_hall_gpio}) 1>;
		};
#endif
	};
};

#if 1
&pio {
	hall_irq: hall_irq {
		pinmux = <MTK_PINMUX(SEC_GPIO_NUM(AP,pio,6), 0)>;
		bias-disable;
	};
};
#endif

#if 0
&${certify_hall_parent} {
	certify_hall_irq: certify_hall_irq {
		pinmux = <MTK_PINMUX(SEC_GPIO_NUM(${certify_hall_gpio}), 0)>;
		bias-disable;
	};
};
#endif

#if 0
&${wacom_hall_parent} {
	hall_wacom_irq: hall_wacom_irq {
		pinmux = <MTK_PINMUX(SEC_GPIO_NUM(${wacom_hall_gpio}), 0)>;
		bias-disable;
	};
};
#endif
/* #include "../fingerprint_el7xx.dtsi" */           /* From fingerprint_el7xx.py */
/*
 * Copyright (c) 2012-2013, The Linux Foundation. All rights reserved.
 *
 * This program is free software; you can redistribute it and/or modify
 * it under the terms of the GNU General Public License version 2 and
 * only version 2 as published by the Free Software Foundation.
 *
 * This program is distributed in the hope that it will be useful,
 * but WITHOUT ANY WARRANTY; without even the implied warranty of
 * MERCHANTABILITY or FITNESS FOR A PARTICULAR PURPOSE.  See the
 * GNU General Public License for more details.
 */

&pio {
	btp_sleep: btp_sleep_enable {
		pins_cmd_dat{
			pinmux = <MTK_PINMUX(SEC_GPIO_NUM(AP,pio,121), 0)>;
#if 0
			bias-pull-down = <MTK_PUPD_SET_R1R0_11>;
#else
			bias-pull-down;
#endif
			drive-strength = <1>;
		};
	};
};

#if 1
&pio {
	btp_ldo_en: btp_ldo_enable {
		pins_cmd_dat{
			pinmux = <MTK_PINMUX(SEC_GPIO_NUM(AP,pio,96), 0)>;
			bias-pull-down;
			drive-strength = <1>;
		};
	};
};
#endif

&pio {
	spi5_set_miso: set_miso {
		pins_cmd_dat{
#if 0
			pinmux = <MTK_PINMUX(SEC_GPIO_NUM(AP,pio,100), 1)>;
#else
			pinmux = <MTK_PINMUX(SEC_GPIO_NUM(AP,pio,100), 1)>;
#endif
			drive-strength = <4>;
		};
	};
	spi5_set_cs: set_cs {
		pins_cmd_dat{
#if 0
			pinmux = <MTK_PINMUX(SEC_GPIO_NUM(AP,pio,99), 1)>;
#else
			pinmux = <MTK_PINMUX(SEC_GPIO_NUM(AP,pio,99), 1)>;
#endif
			drive-strength = <4>;
		};
	};
	spi5_set_mosi: set_mosi {
		pins_cmd_dat{
#if 0
			pinmux = <MTK_PINMUX(SEC_GPIO_NUM(AP,pio,101), 1)>;
#else
			pinmux = <MTK_PINMUX(SEC_GPIO_NUM(AP,pio,101), 1)>;
#endif
			drive-strength = <4>;
		};
	};
	spi5_set_clk: set_clk {
		pins_cmd_dat{
#if 0
			pinmux = <MTK_PINMUX(SEC_GPIO_NUM(AP,pio,98), 1)>;
#else
			pinmux = <MTK_PINMUX(SEC_GPIO_NUM(AP,pio,98), 1)>;
#endif
			drive-strength = <4>;
		};
	};
	spi5_clr_miso: clr_miso {
		pins_cmd_dat{
			pinmux = <MTK_PINMUX(SEC_GPIO_NUM(AP,pio,100), 0)>;
			slew-rate = <0>;
			bias-pull-down;
			input-enable;
			drive-strength = <1>;
		};
	};
	spi5_clr_cs: clr_cs {
		pins_cmd_dat{
			pinmux = <MTK_PINMUX(SEC_GPIO_NUM(AP,pio,99), 0)>;
			slew-rate = <0>;
			bias-pull-down;
			output-low;
			drive-strength = <1>;
		};
	};
	spi5_clr_mosi: clr_mosi {
		pins_cmd_dat{
			pinmux = <MTK_PINMUX(SEC_GPIO_NUM(AP,pio,101), 0)>;
			slew-rate = <0>;
			bias-pull-down;
			output-low;
			drive-strength = <1>;
		};
	};
	spi5_clr_clk: clr_clk {
		pins_cmd_dat{
			pinmux = <MTK_PINMUX(SEC_GPIO_NUM(AP,pio,98), 0)>;
			slew-rate = <0>;
			bias-pull-down;
			output-low;
			drive-strength = <1>;
		};
	};
};

#if 0
&${fps_regul_vdd_3p3} {
	regulator-name = "VDD_BTP_3P3";
};
#endif

#if defined(CONFIG_SEC_FACTORY) || !1
&spi5 {
	status = "okay";
	max-dma = <0x40000>;
#else
&smd {
#endif
	#address-cells = <1>;
	#size-cells = <0>;

	etspi-spi@0 {
		compatible = "etspi,el7xx";
		reg = <0x00>;
		spi-max-frequency = <25000000>;
#if !defined(CONFIG_SEC_FACTORY) && 1
		clocks = <&topckgen_clk CLK_TOP_MAINPLL_D5_D4>,
			<&topckgen_clk CLK_TOP_SPI_SEL>,
			<&infracfg_ao_clk CLK_IFRAO_SPI5>;
		clock-names = "parent-clk", "sel-clk", "spi-clk";
#endif

		pinctrl-names = "default", "pins_poweron", "pins_poweroff";
#if 1
		pinctrl-0 = <&btp_sleep &btp_ldo_en>;
#else
		pinctrl-0 = <&btp_sleep>;
#endif
		pinctrl-1 = <&spi5_set_miso &spi5_set_cs &spi5_set_mosi &spi5_set_clk>;
		pinctrl-2 = <&spi5_clr_miso &spi5_clr_cs &spi5_clr_mosi &spi5_clr_clk>;


		gpio-controller;
		#gpio-cells = <2>;

		etspi-sleepPin = <SEC_GPIO_REF(AP,pio,121) 0>;
#if 0
		etspi-regulator = "VDD_BTP_3P3";
#endif
#if 1
		etspi-ldoPin = <SEC_GPIO_REF(AP,pio,96) 0>;
#endif
		etspi-chipid = "EL721";
		etspi-modelinfo = "A346";
		etspi-position = "11.69,0.00,9.10,9.10,14.80,14.80,12.00,12.00,5.00";
		etspi-rb = "588,-1,-1,FFFFFF";
		controller-data {
			mediatek,tckdly = <1>;
		};
	};
};

/* #include "../mst.dtsi" */                         /* From mst.py */
/* Copyright (c) 2020, Samsung Electronics Corporation. All rights reserved.
 *
 * This program is free software; you can redistribute it and/or modify
 * it under the terms of the GNU General Public License version 2 and
 * only version 2 as published by the Free Software Foundation.
 *
 * This program is distributed in the hope that it will be useful,
 * but WITHOUT ANY WARRANTY; without even the implied warranty of
 * MERCHANTABILITY or FITNESS FOR A PARTICULAR PURPOSE.  See the
 * GNU General Public License for more details.
 */

#if !(0)
&pio {
	mst_pwr_en: sec-mst,mst-pwr-gpio {
		GPIO_CONFIG_PUD(AP,pio,109, FUNC_OUTPUT_LOW, PULL_DOWN);
#if defined(CONFIG_ARCH_EXYNOS) || defined(CONFIG_ARCH_EXYNOS9)
		samsung,pin-con-pdn = <0>;
		samsung,pin-pud-pdn = <1>;
#endif
	};
};
#endif

#if 0
&pio {
	mst_en: sec-mst,mst-en-gpio {
		GPIO_CONFIG_PUD(AP,pio,139, FUNC_OUTPUT_LOW, PULL_DOWN);
#if defined(CONFIG_ARCH_EXYNOS) || defined(CONFIG_ARCH_EXYNOS9)
		samsung,pin-con-pdn = <0>;
		samsung,pin-pud-pdn = <1>;
#endif
	};
};

&pio {
	mst_data: sec-mst,mst-data-gpio {
		GPIO_CONFIG_PUD(AP,pio,138, FUNC_OUTPUT_LOW, PULL_DOWN);
#if defined(CONFIG_ARCH_EXYNOS) || defined(CONFIG_ARCH_EXYNOS9)
		samsung,pin-con-pdn = <0>;
		samsung,pin-pud-pdn = <1>;
#endif
	};
};
#endif

#if 0
&${mst_support_parent} {
	mst_support_gpio: sec-mst,mst-support-gpio {
		GPIO_CONFIG_PUD(${mst_support}, FUNC_INPUT, PULL_NONE);
#if defined(CONFIG_ARCH_EXYNOS) || defined(CONFIG_ARCH_EXYNOS9)
		samsung,pin-con-pdn = <2>;
		samsung,pin-pud-pdn = <0>;
#endif
	};
};
#endif

&smd {
	sec_mst: sec-mst{
		compatible = "sec-mst";
#if !(0)
		sec-mst,mst-pwr-gpio = <SEC_GPIO_REF(AP,pio,109) 0>;
#endif
#if 0
		sec-mst,mst-en-gpio = <SEC_GPIO_REF(AP,pio,139) 0>;
		sec-mst,mst-data-gpio = <SEC_GPIO_REF(AP,pio,138) 0>;
#endif
#if 0
		sec-mst,mst-support-gpio = <SEC_GPIO_REF(${mst_support}) 0>;
#endif

		pinctrl-names = "default";
#if !(0) || 0 || 0
		pinctrl-0 = <
#if !(0)
				&mst_pwr_en 
#endif
#if 0
				&mst_en &mst_data
#endif
#if 0
				&mst_support_gpio
#endif
				>;
#endif
	};
};

/* #include "../pmic_MT6365.dtsi" */                 /* From pmic_MT6365.py */
#if 0 && 0
&mt6359p_vaud18_reg {
	regulator-min-microvolt = <0>;
	regulator-max-microvolt = <0>;
	
	 
};
#endif

#if 0 && 0
&mt6359p_vsim1_reg {
	regulator-min-microvolt = <0>;
	regulator-max-microvolt = <0>;
	
	 
};
#endif

#if 3300000 && 3300000
&mt6359p_vibr_reg {
	regulator-min-microvolt = <3300000>;
	regulator-max-microvolt = <3300000>;
	regulator-always-on;regulator-boot-on;
	 
};
#endif

#if 0 && 0
&mt6359p_vrf12_reg {
	regulator-min-microvolt = <0>;
	regulator-max-microvolt = <0>;
	
	 
};
#endif

#if 0 && 0
&mt6359p_vusb_reg {
	regulator-min-microvolt = <0>;
	regulator-max-microvolt = <0>;
	
	 
};
#endif

#if 0 && 0
&mt6359p_vsram_proc2_reg {
	regulator-min-microvolt = <0>;
	regulator-max-microvolt = <0>;
	
	 
};
#endif

#if 0 && 0
&mt6359p_vio18_reg {
	regulator-min-microvolt = <0>;
	regulator-max-microvolt = <0>;
	
	 
};
#endif

#if 0 && 0
&mt6359p_vcamio_reg {
	regulator-min-microvolt = <0>;
	regulator-max-microvolt = <0>;
	
	 
};
#endif

#if 0 && 0
&mt6359p_vcn18_reg {
	regulator-min-microvolt = <0>;
	regulator-max-microvolt = <0>;
	
	 
};
#endif

#if 0 && 0
&mt6359p_vfe28_reg {
	regulator-min-microvolt = <0>;
	regulator-max-microvolt = <0>;
	
	 
};
#endif

#if 0 && 0
&mt6359p_vcn13_reg {
	regulator-min-microvolt = <0>;
	regulator-max-microvolt = <0>;
	
	 
};
#endif

#if 0 && 0
&mt6359p_vcn33_1_bt_reg {
	regulator-min-microvolt = <0>;
	regulator-max-microvolt = <0>;
	
	 
};
#endif

#if 0 && 0
&mt6359p_vcn33_1_wifi_reg {
	regulator-min-microvolt = <0>;
	regulator-max-microvolt = <0>;
	
	 
};
#endif

#if 0 && 0
&mt6359p_vaux18_reg {
	regulator-min-microvolt = <0>;
	regulator-max-microvolt = <0>;
	
	 
};
#endif

#if 0 && 0
&mt6359p_vsram_others_reg {
	regulator-min-microvolt = <0>;
	regulator-max-microvolt = <0>;
	
	 
};
#endif

#if 0 && 0
&mt6359p_vefuse_reg {
	regulator-min-microvolt = <0>;
	regulator-max-microvolt = <0>;
	
	 
};
#endif

#if 0 && 0
&mt6359p_vxo22_reg {
	regulator-min-microvolt = <0>;
	regulator-max-microvolt = <0>;
	
	 
};
#endif

#if 0 && 0
&mt6359p_vrfck_reg {
	regulator-min-microvolt = <0>;
	regulator-max-microvolt = <0>;
	
	 
};
#endif

#if 0 && 0
&mt6359p_vbif28_reg {
	regulator-min-microvolt = <0>;
	regulator-max-microvolt = <0>;
	
	 
};
#endif

#if 3000000 && 3000000
&mt6359p_vio28_reg {
	regulator-min-microvolt = <3000000>;
	regulator-max-microvolt = <3000000>;
	
	 
};
#endif


#if 0 && 0
&mt6359p_vemc_reg {
	regulator-min-microvolt = <0>;
	regulator-max-microvolt = <0>;
	
	 
};
#endif

#if 0 && 0
&mt6359p_vcn33_2_bt_reg {
	regulator-min-microvolt = <0>;
	regulator-max-microvolt = <0>;
	
	 
};
#endif

#if 0 && 0
&mt6359p_vcn33_2_wifi_reg {
	regulator-min-microvolt = <0>;
	regulator-max-microvolt = <0>;
	
	 
};
#endif

#if 0 && 0
&mt6359p_va12_reg {
	regulator-min-microvolt = <0>;
	regulator-max-microvolt = <0>;
	
	 
};
#endif

#if 0 && 0
&mt6359p_va09_reg {
	regulator-min-microvolt = <0>;
	regulator-max-microvolt = <0>;
	
	 
};
#endif

#if 0 && 0
&mt6359p_vrf18_reg {
	regulator-min-microvolt = <0>;
	regulator-max-microvolt = <0>;
	
	 
};
#endif

#if 0 && 0
&mt6359p_vsram_md_reg {
	regulator-min-microvolt = <0>;
	regulator-max-microvolt = <0>;
	
	 
};
#endif

#if 0 && 0
&mt6359p_vufs_reg {
	regulator-min-microvolt = <0>;
	regulator-max-microvolt = <0>;
	
	 
};
#endif

#if 0 && 0
&mt6359p_vm18_reg {
	regulator-min-microvolt = <0>;
	regulator-max-microvolt = <0>;
	
	 
};
#endif

#if 0 && 0
&mt6359p_vbbck_reg {
	regulator-min-microvolt = <0>;
	regulator-max-microvolt = <0>;
	
	 
};
#endif

#if 0 && 0
&mt6359p_vsram_proc1_reg {
	regulator-min-microvolt = <0>;
	regulator-max-microvolt = <0>;
	
	 
};
#endif

#if 0 && 0
&mt6359p_vsim2_reg {
	regulator-min-microvolt = <0>;
	regulator-max-microvolt = <0>;
	
	 
};
#endif


/* #include "../pmic_MT6360.dtsi" */                 /* From pmic_MT6360.py */
#if 1800000 && 1800000
&mt_pmic_vfp_ldo_reg {
    regulator-min-microvolt = <1800000>;
    regulator-max-microvolt = <1800000>;
    
     
};
#endif

#if 1800000 && 1800000
&mt_pmic_vtp_ldo_reg {
    regulator-min-microvolt = <1800000>;
    regulator-max-microvolt = <1800000>;
    regulator-always-on;regulator-boot-on;
     
};
#endif

#if 0 && 0
&mt_pmic_vmc_ldo_reg {
    regulator-min-microvolt = <0>;
    regulator-max-microvolt = <0>;
    
     
};
#endif

#if 0 && 0
&mt_pmic_vmch_ldo_reg {
    regulator-min-microvolt = <0>;
    regulator-max-microvolt = <0>;
    
     
};
#endif

#if 0 && 0
&mt_pmic_vdram2_ldo_reg {
    regulator-min-microvolt = <0>;
    regulator-max-microvolt = <0>;
    
     
};
#endif
/* #include "../muic_afc_gpio.dtsi" */               /* From muic_afc_gpio.py */
&pio {
	afc_output: afc_output {
		pins_cmd_dat {
			pinmux = <MTK_PINMUX(SEC_GPIO_NUM(AP,pio,12), 0)>;
			slew-rate = <1>;
			output-enable;
			bias-disable;
		};
	};

};

&pio {
	afc_switch: afc_switch {
		pins_cmd_dat {
			pinmux = <MTK_PINMUX(SEC_GPIO_NUM(AP,pio,76), 0)>;
			slew-rate = <1>;
			output-enable;
			bias-disable;
		};
	};

};

#if 0
&${afc_hvdcp_parent} {
	afc_hvdcp: afc_hvdcp {
		pins_cmd_dat {
			pinmux = <MTK_PINMUX(SEC_GPIO_NUM(${afc_hvdcp_gpio}), 0)>;
			slew-rate = <1>;
			output-enable;
			bias-disable;
		};
	};
};
#endif

#if 1
&pio {
	hiccup_switch: hiccup_switch {
		pins_cmd_dat {
			pinmux = <MTK_PINMUX(SEC_GPIO_NUM(AP,pio,97), 0)>;
			slew-rate = <1>;
			output-enable;
			bias-disable;
		};
	};
};
#endif

&smd {
	gpio_afc: gpio_afc {
		compatible = "gpio_afc";
		pinctrl-names = "default";
		pinctrl-0 = <&afc_switch &afc_output
#if 0
			&afc_hvdcp
#endif
#if 1
			&hiccup_switch
#endif
		>;
		status = "okay";
		gpio_afc_data = <SEC_GPIO_REF(AP,pio,12) 0>;
		gpio_afc_switch = <SEC_GPIO_REF(AP,pio,76) 0>;
#if 0
		gpio_afc_hvdcp = <SEC_GPIO_REF(${afc_hvdcp_gpio}) 0>; 
#endif
#if 1
		gpio_hiccup = <SEC_GPIO_REF(AP,pio,97) 0>; 
#endif
	};
};

/* #include "../sensorhub_mt6877_shub.dtsi" */       /* From sensorhub_mt6877_shub.py */
/ {
	fragment@model {
		target-path = "/";
		__overlay__ {
			shub {
				compatible = "shub";
			};
		};
	};
};

/* /home/dpi/qb5_8814/workspace/P4_1716/android/kernel/kmodule/sensorhub/mtk/mt6877_shub/dts/sensorhub_mt6877_shub.a34x.dtsi */
/ {
	fragment@model {
		target-path = "/";
		__overlay__ {
			shub {
				acc-motor-coef = <5>;
				acc-lsm6dsotr-position = <7>;

				mag-ak09918c-position = <7>;
				mag-ak09918c-array = /bits/ 8 <0 0 0 0 0 0 0 0 0
								0 0 0 0 0 0 0 0 0
								0 0 0 0 0 0 0 0 0>;
				mag-mxg4300s-position = <4>;
				mag-mxg4300s-array = /bits/ 8 <41 240 5 136 255 238 3 166 34 231 254 160 0 157 255 182 40 184 0 0 0 0 0 0 0 0 0>;
				fcd-axis = <1>;
				fcd-threshold = <(500)>;
				light-position = /bits/ 32 <26 52 3 67 2 0>;
				brightness-array-len = <11>;
				brightness-array = /bits/ 32 <19 48 54 58 63 67 70 73 75 77 100>;
			};
		};
	};
};

/* #include "../s2mpb03.dtsi" */                     /* From s2mpb03.py */
&sw_i2c0 {
	#address-cells = <1>;
	#size-cells = <0>;
	status = "okay";
	s2mpb03_pmic_0: s2mpb03_pmic@56 {
		compatible = "samsung,s2mpb03pmic";
		reg = <0x56>;
		s2mpb03,wakeup;

		regulators {
			s2mpb03_0_l1: s2mpb03-ldo1 {
				regulator-name = "CAM0_s2mpb03-l1";
				regulator-min-microvolt = <1050000>;
				regulator-max-microvolt = <1050000>;
				
				 
			};

			s2mpb03_0_l2: s2mpb03-ldo2 {
				regulator-name = "CAM0_s2mpb03-l2";
				regulator-min-microvolt = <1100000>;
				regulator-max-microvolt = <1100000>;
				
				 
			};

			s2mpb03_0_l3: s2mpb03-ldo3 {
				regulator-name = "CAM0_s2mpb03-l3";
				regulator-min-microvolt = <1800000>;
				regulator-max-microvolt = <1800000>;
				
				 
			};

			s2mpb03_0_l4: s2mpb03-ldo4 {
				regulator-name = "CAM0_s2mpb03-l4";
				regulator-min-microvolt = <1100000>;
				regulator-max-microvolt = <1100000>;
				
				 
			};

			s2mpb03_0_l5: s2mpb03-ldo5 {
				regulator-name = "CAM0_s2mpb03-l5";
				regulator-min-microvolt = <2150000>;
				regulator-max-microvolt = <2150000>;
				
				 
			};

			s2mpb03_0_l6: s2mpb03-ldo6 {
				regulator-name = "CAM0_s2mpb03-l6";
				regulator-min-microvolt = <2800000>;
				regulator-max-microvolt = <2800000>;
				
				 
			};

			s2mpb03_0_l7: s2mpb03-ldo7 {
				regulator-name = "CAM0_s2mpb03-l7";
				regulator-min-microvolt = <2800000>;
				regulator-max-microvolt = <2800000>;
				
				 
			};
		};
	};
};

/* #include "../sec_direct_charger.dtsi" */          /* From sec_direct_charger.py */

&smd {
	sec-direct-charger {
		status = "okay";
		compatible = "samsung,sec-direct-charger";

		charger,battery_name = "battery";
		charger,main_charger = "sec-mtk-charger";
		charger,direct_charger = "sm5451-charger";

	#if 0
		charger,direct_chargers =
				"sm5451-charger",
				"${direct_charger_name2}";
	#endif

		charger,dchg_min_current = <2000>;

		charger,ta_alert_wa;
	};
};


/* /home/dpi/qb5_8814/workspace/P4_1716/android/kernel/kmodule/battery/suwon/common/sec_direct_charger/dts/a34x/sec_direct_charger.dtsi */

&smd {
	pass-through {
		start_delay = <5000>; /* msec */
		init_delay = <5000>; /* msec */
		min_cap = <200>; /* 0.1 % */
		fixed_sc_cap = <900>; /* 0.1 % */
		max_icl = <3000>; /* mA */
	};
};


/* #include "../sensorhub_shub.dtsi" */              /* From sensorhub_shub.py */
#if 1
&mt_pmic_vtp_ldo_reg {
	regulator-name = "VDD_SENSOR_1P8";
};
#endif
#if 0
&${gpio_sensor_ldo_en_parent} {
	shub_sensor_ldo_en: shub-sensor-ldo-en {
		samsung,pins = SEC_GPIO(${gpio_sensor_ldo_en});
		samsung,pin-function = <1>;
		samsung,pin-pud = <0>;
		samsung,pin-con-pdn = <3>;
		samsung,pin-pud-pdn = <0>;
	};
};
#endif
#if 0
&${gpio_prox_ldo_en_parent} {
	shub_prox_ldo_en: shub-prox-ldo-en {
		samsung,pins = SEC_GPIO(${gpio_prox_ldo_en});
		samsung,pin-function = <1>;
		samsung,pin-pud = <0>;
		samsung,pin-con-pdn = <3>;
		samsung,pin-pud-pdn = <0>;
	};
};
#endif
#if 0
&${gpio_pogo_int_parent} {
	shub_pogo_int: shub-pogo-int {
		GPIO_CONFIG_PUD_DRV(${gpio_pogo_int}, FUNC_INPUT_WAKEUP, PULL_NONE, DRV_LV1);
	};
};
#endif
/ {
	fragment@model {
		target-path = "/";
		__overlay__ {
			shub {
				pinctrl-names = "default";
#if 0 || 0 || 0
				pinctrl-0 = <
#if 0
				&shub_sensor_ldo_en
#endif
#if 0
				&shub_prox_ldo_en
#endif
#if 0
				&shub_pogo_int
#endif
>;
#endif

#if 1
				sensor-vdd-regulator = "VDD_SENSOR_1P8";
#endif

#if 0
				mag-check-nfc = <SEC_GPIO_REF(${gpio_nfc_check}) 0>;
#endif

#if 0
				pogo-int = <SEC_GPIO_REF(${gpio_pogo_int}) 0>;
#endif

#if 0
				sensor-ldo-en = <SEC_GPIO_REF(${gpio_sensor_ldo_en}) 0>;
#endif
#if 0
				prox-ldo-en = <SEC_GPIO_REF(${gpio_prox_ldo_en}) 0>;
#endif
			};
		};
	};
};

/* #include "../nfc_lsi_nfc_2.dtsi" */               /* From nfc_lsi_nfc_2.py */
/*
 * This program is free software; you can redistribute it and/or modify
 * it under the terms of the GNU General Public License version 2 and
 * only version 2 as published by the Free Software Foundation.
 *
 * This program is distributed in the hope that it will be useful,
 * but WITHOUT ANY WARRANTY; without even the implied warranty of
 * MERCHANTABILITY or FITNESS FOR A PARTICULAR PURPOSE.  See the
 * GNU General Public License for more details.
 */

#if 0
#if 0
&${ese_check_parent} {
	ese_check_default: check_default {
		pins_cmd_dat {
			pinmux = <MTK_PINMUX(SEC_GPIO_NUM(${ese_check}), 0)>;
			input-enable;
			bias-disable;
		};
	};
};
#endif

&${ese_spi_parent} {
	ese_spi_bus: ese_spi_bus {
		pins_cmd_dat {
			/* spi func is 2, but this can be different by AP */
			pinmux = <MTK_PINMUX(SEC_GPIO_NUM(${ese_spi_miso}), 2)>,
				<MTK_PINMUX(SEC_GPIO_NUM(${ese_spi_mosi}), 2)>,
				<MTK_PINMUX(SEC_GPIO_NUM(${ese_spi_clk}), 2)>;
			bias-disable;
		};
	};

	ese_spi_bus_suspend: ese_spi_bus_suspend {
		pins_cmd_dat {
			/* spi func is 2, but this can be different by AP */
			pinmux = <MTK_PINMUX(SEC_GPIO_NUM(${ese_spi_miso}), 0)>,
				<MTK_PINMUX(SEC_GPIO_NUM(${ese_spi_mosi}), 0)>,
				<MTK_PINMUX(SEC_GPIO_NUM(${ese_spi_clk}), 0)>;
			input-enable;
			bias-pull-down;
		};
	};

	/*need cs pin controlled by ese driver*/
	ese_spi_cs: ese_spi_cs {
		pins_cmd_dat {
			pinmux = <MTK_PINMUX(SEC_GPIO_NUM(${ese_spi_cs}), 0)>;
			output-high;
			bias-disable;
		};
	};

	ese_spi_cs_suspend: ese_spi_cs_suspend {
		pins_cmd_dat {
			pinmux = <MTK_PINMUX(SEC_GPIO_NUM(${ese_spi_cs}), 0)>;
			output-high;
			bias-disable;
		};
	};
};

&${ese_spi} {
	status = "ok";
	pinctrl-names = "ese_active", "ese_suspend";
	pinctrl-0 = <&ese_spi_bus &ese_spi_cs>;
	pinctrl-1 = <&ese_spi_bus_suspend &ese_spi_cs_suspend>;

	ese_spi@0 {
		compatible = "ese_p3";
		reg = <0>;
		spi-max-frequency = <7000000>;
#if 0
		ese-det-gpio = <SEC_GPIO_REF(${ese_check}) 0>;
		pinctrl-names = "default";
		pinctrl-0 = <&ese_check_default>;
#endif
#if 0
		p3-vdd-supply = <&${ese_pvdd_ldo}>;
#endif
		/*need cs pin controlled by ese driver*/
		ese_p3,cs-gpio = <SEC_GPIO_REF(${ese_spi_cs}) 0>;
	};
};

#if 0
/ {
	fragment@ese_platform {
		target-path = "/";
		__overlay__ {
			ese_platform {
				compatible = "p3_platform";
			};
		};
	};
};
#endif
#endif


&pio {
	nfc_ven: nfc_ven {
		pins_cmd_dat{
			pinmux = <MTK_PINMUX(SEC_GPIO_NUM(AP,pio,107), 0)>;
			output-low;
			bias-disable;
		};
	};
	ven_nc: ven_nc {
		pins_cmd_dat{
			pinmux = <MTK_PINMUX(SEC_GPIO_NUM(AP,pio,107), 0)>;
			input-enable;
			bias-pull-down;
		};
	};
};

&pio {
	nfc_firm: nfc_firm {
		pins_cmd_dat{
			pinmux = <MTK_PINMUX(SEC_GPIO_NUM(AP,pio,108), 0)>;
			output-low;
			bias-disable;
		};
	};
	firm_nc: firm_nc {
		pins_cmd_dat{
			pinmux = <MTK_PINMUX(SEC_GPIO_NUM(AP,pio,108), 0)>;
			input-enable;
			bias-pull-down;
		};
	};
};

&pio {
	nfc_clk_req: nfc_clk_req {
		pins_cmd_dat{
			pinmux =  <MTK_PINMUX(SEC_GPIO_NUM(AP,pio,13), 0)>;
			input-enable;
			bias-pull-down;
		};
	};
	clk_req_nc: clk_req_nc {
		pins_cmd_dat{
			pinmux =  <MTK_PINMUX(SEC_GPIO_NUM(AP,pio,13), 0)>;
			input-enable;
			bias-pull-down;
		};
	};
};

&pio {
	nfc_irq: nfc_irq {
		pins_cmd_dat {
			pinmux = <MTK_PINMUX(SEC_GPIO_NUM(AP,pio,11), 0)>;
			input-enable;
			bias-pull-down;
		};
	};

	irq_nc: irq_nc {
		pins_cmd_dat {
			pinmux = <MTK_PINMUX(SEC_GPIO_NUM(AP,pio,11), 0)>;
			input-enable;
			bias-pull-down;
		};
	};
};

#if 1
&pio {
	nfc_check: nfc_check {
		pins_cmd_dat {
			pinmux = <MTK_PINMUX(SEC_GPIO_NUM(AP,pio,90), 0)>;
			input-enable;
			bias-disable;
		};
	};
};
#endif

#if 0
&${i2c_switch_parent} {
	nfc_i2c_switch: nfc_i2c_switch {
		pins_cmd_dat {
			pinmux = <MTK_PINMUX(SEC_GPIO_NUM(${i2c_switch_gpio}), 0)>;
			output-low;
			bias-disable;
		};
	};
	nfc_i2c_switch_nc: nfc_i2c_switch_nc {
		pins_cmd_dat {
			pinmux = <MTK_PINMUX(SEC_GPIO_NUM(${i2c_switch_gpio}), 0)>;
			input-enable;
			bias-pull-down;
		};
	};
};
#endif

&i2c3 {
	status = "ok";
	clock-frequency = <400000>;
	mediatek,use-open-drain;
	sec_nfc: sec-nfc@27 {
		compatible = "sec-nfc";
		reg = <0x27>;
		interrupt-parent = <&pio>;
		interrupts = <SEC_GPIO_NUM(AP,pio,11) IRQ_TYPE_EDGE_RISING
			SEC_GPIO_NUM(AP,pio,11) 0>;
		sec-nfc,irq-gpio = <SEC_GPIO_REF(AP,pio,11) 0>;
		sec-nfc,ven-gpio = <SEC_GPIO_REF(AP,pio,107) 0>;
		sec-nfc,firm-gpio = <SEC_GPIO_REF(AP,pio,108) 0>;
		sec-nfc,clk_req-gpio = <SEC_GPIO_REF(AP,pio,13) 0>;
#if 1
		nfc_pvdd-supply = <&mt_pmic_vfp_ldo_reg>;
#endif
#if 1
		sec-nfc,check_nfc = <SEC_GPIO_REF(AP,pio,90) 0>;
#endif
#if 0
		sec-nfc,coldreset-gpio = <SEC_GPIO_REF(${ese_reset}) 0>;
#endif
		sec-nfc,clk_req_wake;
		sec-nfc,ldo_control;
/*		sec-nfc,pvdd-gpio = <&pio 154 0>;*/
#if 0
		sec-nfc,i2c_switch-gpio = <SEC_GPIO_REF(${i2c_switch_gpio}) 0>;
#endif
		sec-nfc,nfc_ic_type = "SN4V_RN4V";

		/*sec-nfc,irq_all_trigger;*/
		pinctrl-names = "default", "nfc_nc";

		pinctrl-0 = <&nfc_ven &nfc_firm &nfc_clk_req &nfc_irq
#if 1
					&nfc_check
#endif
#if 0
					&nfc_i2c_switch
#endif
					>;
		pinctrl-1 = <&ven_nc &firm_nc &clk_req_nc &irq_nc
#if 0
					&nfc_i2c_switch_nc
#endif
					>;
	};
};

/* #include "../input_berlin.dtsi" */                /* From input_berlin.py */
&pio {
	berlin_attn_irq: berlin_attn_irq {
		GPIO_CONFIG_PUD(AP,pio,14, FUNC_INPUT_WAKEUP, PULL_NONE);
	};

	berlin_attn_irq_suspend: berlin_attn_irq_suspend {
		GPIO_CONFIG_PUD(AP,pio,14, FUNC_INPUT, PULL_NONE);
	};
};

&i2c0 {
	#address-cells = <1>;
	#size-cells = <0>;
	status = "okay";
	clock-frequency = <400000>;

	tsp_goodix: touchscreen@5d {
		status = "okay";
		compatible = "goodix,berlin";
		reg = <0x5d>;
		pinctrl-names = "on_state", "off_state";
		pinctrl-0 = <&berlin_attn_irq>;
		pinctrl-1 = <&berlin_attn_irq_suspend>;
		tsp_io_ldo-supply = <&NC>;
		tsp_avdd_ldo-supply = <&mt6359p_vio28_reg>;
		sec,irq_gpio = <SEC_GPIO_REF(AP,pio,14) 0>;
		sec,irq_flag = <0x2002>; /* IRQF_TRIGGER_FALLING | IRQF_ONESHOT */
		support_dex_mode;
		sec,enable_sysinput_enabled;
		support_open_short_test;
	};
};

/* /home/dpi/qb5_8814/workspace/P4_1716/android/kernel/kmodule/input/touchscreen/goodix/berlin/dts/input-mtk-tsp-berlin.a34x.dtsi */
&tsp_goodix {
	status = "okay";
	/delete-property/ tsp_io_ldo-supply;
	not_support_io_ldo;
	support_ear_detect_mode;
	support_fod;
	support_fod_lp_mode;
	enable_settings_aot;
	sec,bitmask_unload = <12 0x804>; /* bitshift bitmask. this is for focaltech panel */
	sec,refresh_rate_enable;
	sec,enable_esd_check;

	sec,max_coords = <1080 2340>;
	sec,firmware_name = "tsp_goodix/gt9895_a34x.bin";
	sec,bringup = <0>;

	sec,ic_type = <2>; //GT9895
	sec,max_drv_num = <17>;
	sec,max_sen_num = <35>;
	sec,drv_map = <35 36 37 38 39 40 41 42 43 44
			45 46 47 48 49 50 51>;
	sec,sen_map = <0 1 2 3 4 5 6 7 8 9 10 11 12
			13 14 15 16 17 18 19 20 21
			22 23 24 25 26 27 28 29 30
			31 32 33 34>;
	sec,short_test_time_reg = <0x1479E>;
	sec,short_test_status_reg = <0x13400>;
	sec,short_test_result_reg = <0x13408>;
	sec,drv_drv_reg = <0x13446>;
	sec,sen_sen_reg = <0x136EE>;
	sec,drv_sen_reg = <0x14152>;
	sec,diff_code_reg = <0x14734>;
	sec,production_test_addr = <0x15D4C>;
	sec,switch_freq_cmd = <0xB1>;
	sec,switch_cfg_cmd = <0x64>;
	sec,snr_cmd = <0x65>;
	sec,sensitive_cmd = <0x66>;

	sec,isp_ram_reg = <0x23800>;
	sec,flash_cmd_reg = <0x12400>;
	sec,isp_buffer_reg = <0x12410>;
	sec,config_data_reg = <0x3E000>;
	sec,misctl_reg = <0xD804>;
	sec,watch_dog_reg = <0xD040>;
	sec,config_id_reg = <0x10076>;
	sec,enable_misctl_val = <0x20700000>;
#if defined(CONFIG_SEC_FACTORY)
	sec,specific_fw_update_ver = <0x00040000>;
#endif
	goodix,edgehandler_direction_max = <5>;
};

/* #include "../sensors_isg5320a.dtsi" */            /* From sensors_isg5320a.py */
#if 1

&i2c7 {
	#address-cells = <1>;
	#size-cells = <0>;
	status = "okay";
	clock-frequency = <400000>;
	pinctrl-names = "default";
#if 0
	pinctrl-0 = <&grip_ldo_en>;
#endif

	isg5320a: isg5320a-i2c@2C {
		compatible = "isg5320a";
		status = "okay";
		reg = <0x2C>;
		pinctrl-names = "default";
		pinctrl-0 = <&grip_int>;

		interrupt-parent = <SEC_GPIO_TYPE(AP,pio,17)>;
		interrupts = <SEC_GPIO_NUM(AP,pio,17) 0>;

		isg5320a,irq-gpio = <SEC_GPIO_REF(AP,pio,17) 0>;
		isg5320a,hallic_detect = <1>;
		isg5320a,hallic_cert_detect = <1>;
#if 1
		isg5320a,reg_num = <>;
		isg5320a,set_reg = /bits/ 8 <
		
		>;
#endif
	};
};

&pio {
	grip_int: grip-int {
		pins_cmd_dat {
			pinmux = <MTK_PINMUX(SEC_GPIO_NUM(AP,pio,17), 0)>;
			slew-rate = <0>;
			bias-disable;
		};
	};
};

#if 0
&${gpio_grip_en_parent} {
	grip_ldo_en: grip-ldo-en {
		pins_cmd_dat {
			pinmux = <MTK_PINMUX(SEC_GPIO_NUM(${gpio_grip_en}), 0)>;
			slew-rate = <1>;
			bias-disable;
			output-high;
		};
	};
};
#endif

#if 0
&pio {
	grip_i2c: grip-i2c {
		pins_cmd0_dat {
			pinmux = <MTK_PINMUX(SEC_GPIO_NUM(AP,pio,135), 0)>;
			slew-rate = <0>;
			bias-disable;
		};
		pins_cmd1_dat {
			pinmux = <MTK_PINMUX(SEC_GPIO_NUM(AP,pio,134), 0)>;
			slew-rate = <0>;
			bias-disable;
		};
	};
};
#endif
#endif /*isg5320a*/



#if 0

&${i2c_grip_sub} {
	#address-cells = <1>;
	#size-cells = <0>;
	status = "okay";
	clock-frequency = <400000>;
	pinctrl-names = "default";
#if 0
	pinctrl-0 = <&grip_sub_ldo_en>;
#endif
	isg5320a_sub: isg5320a-sub-i2c@28 {
		compatible = "isg5320a_sub";
		status = "okay";
		reg = <0x28>;
		pinctrl-names = "default";
		pinctrl-0 = <&grip_sub_int>;

		interrupt-parent = <SEC_GPIO_TYPE(${gpio_grip_sub_irq})>;
		interrupts = <SEC_GPIO_NUM(${gpio_grip_sub_irq}) 0>;

		isg5320a_sub,irq-gpio = <SEC_GPIO_REF(${gpio_grip_sub_irq}) 0>;
		isg5320a_sub,hallic_detect = <1>;
		isg5320a_sub,hallic_cert_detect = <1>;
#if 1
		isg5320a_sub,reg_num = <>;
		isg5320a_sub,set_reg = /bits/ 8 <
		
		>;
#endif
	};
};

&${gpio_grip_sub_irq_parent} {
	grip_sub_int: grip-sub-int {
		pins_cmd_dat {
			pinmux = <MTK_PINMUX(SEC_GPIO_NUM(${gpio_grip_sub_irq}), 0)>;
			slew-rate = <0>;
			bias-disable;
		};
	};
};

#if 0
&${gpio_grip_en_parent} {
	grip_sub_ldo_en: grip-sub-ldo-en {
		pins_cmd_dat {
			pinmux = <MTK_PINMUX(SEC_GPIO_NUM(${gpio_grip_sub_en}), 0)>;
			slew-rate = <1>;
			bias-disable;
			output-high;
		};
	};
};
#endif

#if 0
&${gpio_grip_sub_i2c_parent} {
	grip_sub_i2c: grip-sub-i2c {
		pins_cmd0_dat {
			pinmux = <MTK_PINMUX(SEC_GPIO_NUM(${gpio_grip_sub_i2c_sda}), 0)>;
			slew-rate = <0>;
			bias-disable;
		};
		pins_cmd1_dat {
			pinmux = <MTK_PINMUX(SEC_GPIO_NUM(${gpio_grip_sub_i2c_scl}), 0)>;
			slew-rate = <0>;
			bias-disable;
		};
	};
};
#endif

#endif /*isg5320a_sub*/

/* /home/dpi/qb5_8814/workspace/P4_1716/android/kernel/kmodule/sensors/isg5320a/dts/isg5320a_mtk.a34x.dtsi */
&isg5320a {
	reg = <0x28>;
	isg5320a,hallic_detect = <0>;
	isg5320a,hallic_cert_detect = <0>;
	isg6320,reg_num = <151>;
	isg5320a,set_reg = /bits/ 8 <
		0x05 0xFC
		0x06 0xF0
		0x07 0x13
		0x08 0x01
		0x09 0x80
		0x0A 0x20
		0x0B 0x00
		0x0C 0x00
		0x12 0x89
		0x19 0x8A
		0x1B 0x22
		0x1D 0x19
		0x1E 0x00
		0x1F 0x18
		0x20 0x05
		0x21 0x10
		0x22 0x10
		0x23 0x00
		0x24 0x00
		0x25 0x05
		0x26 0x05
		0x27 0x10
		0x28 0x19
		0x29 0x00
		0x2A 0x19
		0x2B 0x00
		0x2C 0x00
		0x2D 0x19
		0x2F 0x18
		0x30 0xC0
		0x41 0x11
		0x60 0xF0
		0x61 0x8F
		0x62 0x07
		0x63 0x00
		0x64 0x00
		0x65 0x44
		0x66 0x3C
		0x67 0x01
		0x68 0x00
		0x69 0x00
		0x6A 0x10
		0x6B 0x00
		0x6C 0x10
		0x6D 0x40
		0x6E 0x22
		0x6F 0x00
		0x70 0x01
		0x71 0x60
		0x72 0xFF
		0x73 0xFF
		0x74 0xFF
		0x7B 0x08
		0x7C 0x00
		0x7D 0x0C
		0x7E 0x00
		0x7F 0xF8
		0x80 0xF8
		0x81 0x00
		0x82 0xF0
		0x83 0xF0
		0x84 0xF0
		0x85 0xF0
		0x86 0xF0
		0x87 0xF0
		0x88 0x00
		0x89 0x00
		0x8A 0x08
		0x8B 0x00
		0x8C 0x02
		0x8D 0x00
		0x99 0x21
		0x9A 0x3C
		0x9B 0x01
		0x9C 0x2C
		0x9D 0x00
		0x9E 0x00
		0x9F 0x00
		0xA0 0x96
		0xA1 0xC0
		0xA2 0x22
		0xA3 0x00
		0xA4 0x08
		0xA5 0x60
		0xA6 0xFF
		0xA7 0xFF
		0xA8 0xFF
		0xA9 0x00
		0xAF 0x40
		0xB0 0x00
		0xB1 0x60
		0xB2 0x00
		0xB3 0xD0
		0xB4 0x10
		0xB5 0x28
		0xB6 0xFD
		0xB7 0xF6
		0xB8 0xFD
		0xB9 0xDE
		0xBA 0xFD
		0xBB 0xF0
		0xBC 0x00
		0xBD 0xFF
		0xBE 0x01
		0xBF 0x5E
		0xC0 0x00
		0xC1 0x6E
		0xC2 0xF0
		0xC3 0x00
		0xC4 0x00
		0xC5 0x00
		0x13 0xBA
		0x18 0xF9
		0x1C 0x18
		0x35 0x00
		0x36 0x00
		0x3A 0x0A
		0x3B 0x50
		0x3C 0x0A
		0x3D 0x50
		0x3E 0x60
		0x94 0x10
		0x95 0xB0
		0x96 0x06
		0x2E 0x15
		0x0E 0xE0
		0x0F 0x1E
		0x10 0x00
		0x11 0xC1
		0xD0 0xE0
		0xD1 0x02
		0xD2 0x00
		0xD3 0xFF
		0xD4 0xFF
		0xD5 0x10
		0xD6 0x3C
		0xD7 0xFF
		0xD8 0x1E
		0xD9 0x60
		0xDA 0x7F
		0xDB 0xE0
		0xDC 0x00
		0xDB 0xFF
		0x76 0x08
		0x77 0x00
		0x79 0x02
		0x7A 0x00
		0xAA 0x32
		0xAB 0xC8
		0xAD 0x04
		0xAE 0x00
		>;
};

/* #include "../battery_common.dtsi" */              /* From battery_common.py */
#include <dt-bindings/battery/sec-battery.h>

&smd {
	sec_battery: battery {
		status = "okay";
		compatible = "samsung,sec-battery";
		battery,vendor = "Battery";
		battery,charger_name = "sec-direct-charger";
		battery,fuelgauge_name = "mtk-fg-battery";
		battery,technology = <2>; /* POWER_SUPPLY_TECHNOLOGY_LION */
		battery,chip_vendor = "NONE";

		battery,batt_data_version = <1>;

		battery,adc_check_count = <5>;
		battery,temp_check_type = <SEC_BATTERY_TEMP_CHECK_NONE>;
		battery,usb_temp_check_type = <SEC_BATTERY_TEMP_CHECK_NONE>;
		battery,chg_temp_check_type = <SEC_BATTERY_TEMP_CHECK_NONE>;
		battery,wpc_temp_check_type = <SEC_BATTERY_TEMP_CHECK_NONE>;
		battery,lrp_temp_check_type = <SEC_BATTERY_TEMP_CHECK_NONE>;

		battery,thermal_source = <SEC_BATTERY_THERMAL_SOURCE_NONE>; /* SEC_BATTERY_THERMAL_SOURCE_NONE */
		battery,usb_thermal_source = <SEC_BATTERY_THERMAL_SOURCE_NONE>; /* SEC_BATTERY_THERMAL_SOURCE_NONE */
		battery,chg_thermal_source = <SEC_BATTERY_THERMAL_SOURCE_NONE>; /* SEC_BATTERY_THERMAL_SOURCE_NONE */
		battery,wpc_thermal_source = <SEC_BATTERY_THERMAL_SOURCE_NONE>; /* SEC_BATTERY_THERMAL_SOURCE_NONE */

		battery,inbat_ocv_type =  <SEC_BATTERY_OCV_NONE>;

		battery,polling_time = <10 30 30 30 3600>;

		battery,cable_check_type = <SEC_BATTERY_CABLE_CHECK_PSY>;
		battery,cable_source_type = <SEC_BATTERY_CABLE_SOURCE_EXTERNAL>;
		battery,polling_type = <SEC_BATTERY_MONITOR_ALARM>; /* SEC_BATTERY_MONITOR_ALARM */
		battery,monitor_initial_count = <0>;

		battery,battery_check_type = <0>; /* SEC_BATTERY_CHECK_NONE */

		battery,ovp_uvlo_check_type = <SEC_BATTERY_OVP_UVLO_CHGPOLLING>; /* SEC_BATTERY_OVP_UVLO_CHGPOLLING */

		battery,temp_check_count = <1>;

		battery,usb_protection_temp = <610>;
		battery,temp_gap_bat_usb = <200>;
		battery,overheatlimit_threshold = <700>;
		battery,overheatlimit_recovery = <680>;
		battery,wire_warm_overheat_thresh = <500>;
		battery,wire_normal_warm_thresh = <420>;
		battery,wire_cool1_normal_thresh = <180>;
		battery,wire_cool2_cool1_thresh = <150>;
		battery,wire_cool3_cool2_thresh = <50>;
		battery,wire_cold_cool3_thresh = <0>;
		battery,wireless_warm_overheat_thresh = <500>;
		battery,wireless_normal_warm_thresh = <420>;
		battery,wireless_cool1_normal_thresh = <180>;
		battery,wireless_cool2_cool1_thresh = <150>;
		battery,wireless_cool3_cool2_thresh = <50>;
		battery,wireless_cold_cool3_thresh = <0>;
		battery,tx_high_threshold = <500>;
		battery,tx_high_recovery = <450>;
		battery,tx_low_threshold = <0>;
		battery,tx_low_recovery = <50>;

		battery,wire_warm_current = <1573>;	/* 0.36C */
		battery,wire_cool1_current = <3146>;	/* 0.72C */
		battery,wire_cool2_current = <1048>;	/* 0.24C */
		battery,wire_cool3_current = <437>;	/* 0.1C */
		battery,wireless_warm_current = <1048>;		/* 0.24C */
		battery,wireless_cool1_current = <3146>;	/* 0.72C */
		battery,wireless_cool2_current = <1048>;	/* 0.24C */
		battery,wireless_cool3_current = <437>;		/* 0.1C */

		battery,full_check_type = <SEC_BATTERY_FULLCHARGED_CHGPSY>;
		battery,full_check_type_2nd = <SEC_BATTERY_FULLCHARGED_CHGPSY>;
		battery,full_check_count = <1>;
		battery,chg_gpio_full_check = <0>;
		battery,chg_polarity_full_check = <1>;

		battery,chg_high_temp = <470>;
		battery,chg_high_temp_recovery = <450>;
		battery,chg_input_limit_current = <1000>;
		battery,chg_charging_limit_current = <1900>;

		battery,dchg_high_temp = <520>;
		battery,dchg_high_temp_recovery = <460>;
		battery,dchg_high_batt_temp = <400>;
		battery,dchg_high_batt_temp_recovery = <380>;
		battery,dchg_input_limit_current = <1000>;
		battery,dchg_charging_limit_current = <2000>;

		battery,wpc_temp_control_source = <TEMP_CONTROL_SOURCE_BAT_THM>;
		battery,wpc_high_temp = <400>;
		battery,wpc_high_temp_recovery = <380>;
		battery,wpc_input_limit_current = <800>;
		battery,wpc_charging_limit_current = <1000>;
		battery,wpc_temp_lcd_on_control_source = <TEMP_CONTROL_SOURCE_BAT_THM>;
		battery,wpc_lcd_on_input_limit_current = <800>;

		battery,wpc_store_high_temp = <360>;
		battery,wpc_store_high_temp_recovery = <340>;
		battery,wpc_store_charging_limit_current = <400>;
		battery,wpc_store_lcd_on_high_temp = <360>;
		battery,wpc_store_lcd_on_high_temp_rec = <300>;
		battery,wpc_store_lcd_on_charging_limit_current = <400>;

		battery,fcc_by_tx = <1200>;

		battery,sleep_mode_limit_current = <800>;
		battery,wc_full_input_limit_current = <100>;

		battery,ta_alert_wa;

		battery,mix_high_temp = <420>;
		battery,mix_high_chg_temp = <500>;
		battery,mix_high_temp_recovery = <390>;

		/* battery,usb_conn_slope_avg = <9>; */

		/* battery,enable_mix_v2; */
		/* if you want to use mix_v2 concept, add "battery,enable_mix_v2;" */
		battery,mix_v2_lrp_recov = <460>;
		battery,mix_v2_lrp_cond = <480>;
		battery,mix_v2_bat_cond = <480>;
		battery,mix_v2_chg_cond = <0>;	/* 0 means no use chg thm condition */
		battery,mix_v2_dchg_cond = <0>; /* 0 means no use dchg thm condition */

		battery,full_condition_type = <(SEC_BATTERY_FULL_CONDITION_NOTIMEFULL | SEC_BATTERY_FULL_CONDITION_VCELL)>;
		battery,full_condition_soc = <93>;
		/* battery,full_condition_vcell = FV - 50mV set when variable is parsed */

		battery,recharge_check_count = <1>;
		battery,recharge_condition_type = <SEC_BATTERY_RECHARGE_CONDITION_VCELL>;
		battery,recharge_condition_soc = <98>;
		/* battery,recharge_condition_vcell = FV - 70mV set when variable is parsed */

		battery,charging_reset_time = <0>;

		battery,chg_float_voltage = <4350>;

		battery,pre_afc_work_delay = <2000>;
		battery,pre_wc_afc_work_delay = <4000>;
		battery,pre_afc_input_current = <500>;
		battery,pre_wc_afc_input_current = <500>;

		battery,swelling_high_rechg_voltage = <4000>;
		/*battery,swelling_low_rechg_voltage = FV - 150mA set when variable is parsed */

		battery,siop_icl = <1200>;
		battery,siop_fcc = <1800>;
		battery,siop_hv_icl = <700>;
		battery,siop_hv_icl_2nd = <550>;
		battery,siop_hv_fcc = <1800>;
		battery,siop_apdo_icl = <1000>;
		battery,siop_apdo_fcc = <2000>;

		battery,siop_wpc_icl = <600>;
		battery,siop_wpc_fcc = <1000 500 100>; /* siop_level 70 10 0 */
		battery,siop_hv_wpc_icl = <700>;
		battery,siop_hv_wpc_fcc = <1000 500 100>; /* siop_level 70 10 0 */
		battery,siop_store_hv_wpc_icl = <450>;
		battery,store_mode_buckoff;

		/* trig, recov */
		battery,temp_table_LRP_45W = <385 365>;

		battery,rp_current_rp1 = <500>;
		battery,rp_current_rp2 = <1500>;
		battery,rp_current_rp3 = <3000>;
		battery,rp_current_rdu_rp3 = <2100>;
		battery,rp_current_abnormal_rp3 = <1800>;

		battery,pd_charging_charge_power = <15000>;
		battery,max_charging_current = <2350>;

		battery,store_mode_charging_max = <70>;
		battery,store_mode_charging_min = <60>;

		battery,wireless_cc_cv = <85>;
		battery,wireless_otg_input_current = <900>;

		/* Calculate Based on Offsets from float voltage, full_condition_vcell and recharge_condition_vcell */
		/* if you want to use age_data_by_common_offset concept add battery,age_data_by_common_offset; */

		battery,age_data_cycle = <0 300 400 700 1000>;
		battery,age_data_full_condition_soc = <93 92 91 90 89>;
		battery,age_data_common_offset = <0 20 40 110>;
		/* battery,age_data_max_charging_current_offset = <0 100 200 300 400>; */

		/* cycle, chg_float_voltage, recharge_condition_vcell, full_condition_vcell, full_condition_soc, step charging condition */
		battery,age_data = <0 4350 4280 4250 93
			300 4330 4260 4230 92
			400 4310 4240 4210 91
			700 4290 4220 4190 90
			1000 4240 4170 4140 89>;


		battery,health_condition_cycle = <900 1200 1500>;
		battery,health_condition_asoc = <0 0 0>; /* Default ASOC Disabled */

		battery,max_input_voltage = <9000>; /* mV */
		battery,max_input_current = <3000>;  /* mA */

		battery,cisd_alg_index = <8>;
		battery,cisd_max_voltage_thr = <4400>; /* batttery ovp dettection voltage */
		battery,ignore_cisd_index = <0 0>;
		battery,ignore_cisd_index_d = <0 80>; /* Do not use BUCK_OFF_PER_DAY, DROP_SENSOR_PER_DAY */

		battery,expired_time = <10800>;
		battery,recharging_expired_time = <5400>;

		battery,battery_full_capacity = <3300>;

		battery,ttf_capacity = <3500>;
		battery,cv_data = <
				3228	864	1534
				3133	866	1524
				3067	872	1493
				3019	874	1483
				2929	879	1452
				2896	881	1442
				2843	883	1431
				2792	885	1421
				2754	887	1411
				2695	892	1380
				2660	893	1370
				2625	895	1360
				2580	897	1349
				2531	898	1339
				2492	902	1319
				2450	903	1309
				2410	905	1298
				2348	908	1278
				2296	909	1268
				2263	910	1257
				2214	915	1227
				2182	916	1216
				2147	919	1196
				2103	920	1186
				2051	922	1175
				2019	924	1155
				1981	927	1134
				1948	928	1124
				1911	930	1104
				1879	932	1093
				1834	933	1083
				1795	935	1063
				1761	938	1032
				1722	942	1001
				1689	944	981
				1649	946	960
				1592	948	940
				1532	950	919
				1493	954	878
				1462	955	868
				1410	958	827
				1362	959	817
				1338	960	807
				1291	964	756
				1264	968	715
				1237	968	704
				1213	969	694
				1169	974	633
				1127	975	622
				1105	975	612
				1073	980	541
				1049	982	510
				1010	983	489
				993	984	479
				972	986	448
				955	988	407
				932	990	387
				881	990	377
				864	996	356
				761	1000	307
				710	1000	297
				688	1000	287
				668	1000	235
				658	1000	215
				647	1000	184
				635	1000	153
				622	1000	123
				610	1000	92
				596	1000	61
				583	1000	31
				571	1000	0
				>;

#if 1
		io-channels = <&auxadc 3>;
		io-channel-names = "adc-chg-temp", "n/a", "n/a", "n/a", "n/a", "n/a", "n/a", "n/a";
#endif
#if 0
	/*EUR_DETECTION_NODE*/
	battery,eur_detection = <SEC_GPIO_REF(${eur_detection}) 0 >;
#endif
	};

	/* sec_battery_cable
	 *   0	UNKNOWN,
	 *   1	NONE,
	 *   2	PREPARE_TA,
	 *   3	TA,
	 *   4	USB,
	 *   5	USB_CDP,
	 *   6	9V_TA,
	 *   7	9V_ERR,
	 *   8	9V_UNKNOWN,
	 *   9	12V_TA,
	 *  10	WIRELESS,
	 *  11	HV_WIRELESS,
	 *  12	PMA_WIRELESS,
	 *  13	WIRELESS_PACK,
	 *  14	CABLE_WIRELESS_HV_PACK,
	 *  15	WIRELESS_STAND,
	 *  16	WIRELESS_HV_STAND,
	 *  17	QC20,
	 *  18	QC30,
	 *  19	PDIC,
	 *  20	UARTOFF,
	 *  21	OTG,
	 *  22	LAN_HUB,
	 *  23	POWER_SHARING,
	 *  24	HMT_CONNECTED,
	 *  25	HMT_CHARGE,
	 *  26	HV_TA_CHG_LIMIT,
	 *  27	WIRELESS_VEHICLE,
	 *  28	WIRELESS_HV_VEHICLE,
	 *  29	PREPARE_WIRELESS_HV,
	 *  30  TIMEOUT,
	 *  31  SMART_OTG,
	 *  32  SMART_NOTG,
	 *  33  WIRELESS_TX,
	 *  34	HV_WIRELESS_20,
	 *  35	HV_WIRELESS_20_LIMIT,
	 *  36	WIRELESS_FAKE,
	 *  37  PREPARE_WIRELESS_20,
	 *  38	CABLE_PDIC_APDO,
	 *  39  CABLE_POGO,
	 *  40  CABLE_POGO_9V,
	 *  41  FPDO_DC,
	 *  42	CABLE_MAX,
	 */
	sec_battery_cable: cable-info {
		default_input_current = <1800>;
		default_charging_current = <2100>;
		full_check_current_1st = <350>;
		full_check_current_2nd = <200>;

		current_group_1 {
			cable_number = <
				SEC_BATTERY_CABLE_PREPARE_TA
				SEC_BATTERY_CABLE_PDIC
				SEC_BATTERY_CABLE_OTG
				SEC_BATTERY_CABLE_LAN_HUB
				SEC_BATTERY_CABLE_POWER_SHARING>;
			input_current = <500>;
			charging_current = <500>;
		};
		current_group_2 {
			cable_number = <
				SEC_BATTERY_CABLE_HMT_CHARGE
				SEC_BATTERY_CABLE_SMART_OTG>;
			input_current = <1000>;
			charging_current = <1000>;
		};
		current_group_3 {
			cable_number = <
				SEC_BATTERY_CABLE_USB_CDP
				SEC_BATTERY_CABLE_SMART_NOTG>;
			input_current = <1500>;
			charging_current = <1500>;
		};
		current_group_4 {
			cable_number = <SEC_BATTERY_CABLE_9V_TA SEC_BATTERY_CABLE_9V_ERR
				SEC_BATTERY_CABLE_9V_UNKNOWN SEC_BATTERY_CABLE_QC20 SEC_BATTERY_CABLE_QC30>;
			input_current = <1650>;
			charging_current = <2350>;
		};
		current_group_5 {
			cable_number = <SEC_BATTERY_CABLE_12V_TA>;
			input_current = <1650>;
			charging_current = <2350>;
		};
		current_group_6 {
			cable_number = <
				SEC_BATTERY_CABLE_WIRELESS
				SEC_BATTERY_CABLE_PMA_WIRELESS
				SEC_BATTERY_CABLE_WIRELESS_STAND
				SEC_BATTERY_CABLE_WIRELESS_VEHICLE
				SEC_BATTERY_CABLE_WIRELESS_FAKE>;
			input_current = <800>;
			charging_current = <2350>;
		};
		current_group_7 {
			cable_number = <SEC_BATTERY_CABLE_WIRELESS_PACK>;
			input_current = <700>;
			charging_current = <2350>;
		};
		current_group_8 {
			cable_number = <SEC_BATTERY_CABLE_HMT_CONNECTED>;
			input_current = <1000>;
			charging_current = <450>;
		};
		current_group_9 {
			cable_number = <SEC_BATTERY_CABLE_HV_TA_CHG_LIMIT>;
			input_current = <1800>;
			charging_current = <1800>;
		};
		current_group_10 {
			cable_number = <
				SEC_BATTERY_CABLE_HV_WIRELESS
				SEC_BATTERY_CABLE_WIRELESS_HV_PACK
				SEC_BATTERY_CABLE_WIRELESS_HV_STAND
				SEC_BATTERY_CABLE_WIRELESS_HV_VEHICLE
				SEC_BATTERY_CABLE_HV_WIRELESS_20_LIMIT>;
			input_current = <650>;
			charging_current = <2350>;
		};
		current_group_11 {
			cable_number = <
				SEC_BATTERY_CABLE_PREPARE_WIRELESS_HV
				SEC_BATTERY_CABLE_PREPARE_WIRELESS_20>;
			input_current = <500>;
			charging_current = <1200>;
		};
		current_group_12 {
			cable_number = <
				SEC_BATTERY_CABLE_NONE
				SEC_BATTERY_CABLE_USB
				SEC_BATTERY_CABLE_TIMEOUT>;
			input_current = <475>;
			charging_current = <550>;
		};
		current_group_13 {
			cable_number = <SEC_BATTERY_CABLE_HV_WIRELESS_20>;
			input_current = <1200>;
			charging_current = <2350>;
		};
		current_group_14 {
			cable_number = <SEC_BATTERY_CABLE_WIRELESS_TX>;
			input_current = <800>;
			charging_current = <2350>;
		};
	};
	sec_battery_wireless_power_info: wireless-power-info {
		count = <11>;
		current_group_0 {
			wireless_power_class = <2>;
			vout = <9000>;
			input_current_limit = <830>;
			fast_charging_current = <3150>;
			ttf_charge_current = <1500>;
			rx_power = <7500>;
		};
		current_group_1 {
			wireless_power_class = <2>;
			vout = <10000>;
			input_current_limit = <750>;
			fast_charging_current = <3150>;
			ttf_charge_current = <1500>;
			rx_power = <7500>;
		};
		current_group_2 {
			wireless_power_class = <2>;
			vout = <11000>;
			input_current_limit = <680>;
			fast_charging_current = <3150>;
			ttf_charge_current = <1500>;
			rx_power = <7500>;
		};
		current_group_3 {
			wireless_power_class = <2>;
			vout = <12000>;
			input_current_limit = <625>;
			fast_charging_current = <3150>;
			ttf_charge_current = <1500>;
			rx_power = <7500>;
		};
		current_group_4 {
			wireless_power_class = <2>;
			vout = <9000>;
			input_current_limit = <1330>;
			fast_charging_current = <3150>;
			ttf_charge_current = <2175>;
			rx_power = <12000>;
		};
		current_group_5 {
			wireless_power_class = <2>;
			vout = <11000>;
			input_current_limit = <1090>;
			fast_charging_current = <3150>;
			ttf_charge_current = <2100>;
			rx_power = <12000>;
		};
		current_group_6 {
			wireless_power_class = <2>;
			vout = <12000>;
			input_current_limit = <1000>;
			fast_charging_current = <3150>;
			ttf_charge_current = <2100>;
			rx_power = <12000>;
		};
		current_group_7 {
			wireless_power_class = <2>;
			vout = <11000>;
			input_current_limit = <1360>;
			fast_charging_current = <3150>;
			ttf_charge_current = <2300>;
			rx_power = <15000>;
		};
		current_group_8 {
			wireless_power_class = <2>;
			vout = <12000>;
			input_current_limit = <1250>;
			fast_charging_current = <3150>;
			ttf_charge_current = <2300>;
			rx_power = <15000>;
		};
		current_group_9 {
			wireless_power_class = <2>;
			vout = <13000>;
			input_current_limit = <1150>;
			fast_charging_current = <3150>;
			ttf_charge_current = <2300>;
			rx_power = <15000>;
		};
		current_group_10 {
			wireless_power_class = <2>;
			vout = <10000>;
			input_current_limit = <1100>;
			fast_charging_current = <3150>;
			ttf_charge_current = <2300>;
			rx_power = <11000>;
		};
	};
};

/* /home/dpi/qb5_8814/workspace/P4_1716/android/kernel/kmodule/battery/suwon/common/dts/a34x/battery_common.dtsi */
#define MAX_FV 4420
#define MAX_FCC 3000

#define DCHG_ICL 1100
#define DCHG_FCC 2200

&sec_battery {
		pinctrl-names = "default";

		battery,chip_vendor = "MTK";

		battery,adc_read_type = <SEC_BATTERY_ADC_RAW>;
		battery,temp_check_type = <SEC_BATTERY_TEMP_CHECK_ADC>;
		battery,chg_temp_check_type = <SEC_BATTERY_TEMP_CHECK_ADC>;
		battery,dchg_temp_check_type = <SEC_BATTERY_TEMP_CHECK_TEMP>;
		battery,lrp_temp_check_type = <SEC_BATTERY_TEMP_CHECK_TEMP>;

		battery,thermal_source = <SEC_BATTERY_THERMAL_SOURCE_FG_ADC>;
		battery,chg_thermal_source = <SEC_BATTERY_THERMAL_SOURCE_ADC>;
		battery,dchg_thermal_source = <SEC_BATTERY_THERMAL_SOURCE_ADC>;
		battery,dctp_by_cgtp;

		battery,temp_table_adc = <
					229 255 281 332 380 445 505 591 690 831
					933 1056 1202 1355 1511 1695 1834 1995 2133 2261
					2367 2464 2558
					>;
		battery,temp_table_data = <
					900 850 800 750 700 650 600 550 500 450
					400 350 300 250 200 150 100 50 0 (-50)
					(-100) (-150) (-200)
					>;

		battery,chg_temp_table_adc = <
					320 386 460 545 607 720 806 937 1139 1324
					1556 1780 2029 2285 2589 2892 3155 3328 3590 3828
					4029 4081 4095
					>;
		battery,chg_temp_table_data = <
					900 850 800 750 700 650 600 550 500 450
					400 350 300 250 200 150 100 50 0 (-50)
					(-100) (-150) (-200)
					>;

		battery,usb_protection;
		battery,temp_check_count = <1>;
		battery,wire_warm_overheat_thresh = <500>;
		battery,wire_normal_warm_thresh = <420>;
		battery,wire_cool1_normal_thresh = <180>;
		battery,wire_cool2_cool1_thresh = <150>;
		battery,wire_cool3_cool2_thresh = <50>;
		battery,wire_cold_cool3_thresh = <0>;

		battery,wire_warm_current = <3500>;	/* 0.72C */
		battery,wire_cool1_current = <MAX_FCC>; /* 0.72C */
		battery,wire_cool2_current = <1150>;	/* 0.24C */
		battery,wire_cool3_current = <450>;	/* 0.1C */

		battery,high_temp_topoff = <250>;
		battery,low_temp_topoff = <250>;
		battery,high_temp_float = <4200>;
		battery,low_temp_float = <MAX_FV>;

		battery,chg_high_temp = <590>;
		battery,chg_high_temp_recovery = <550>;
		battery,chg_input_limit_current = <1000>;
		battery,chg_charging_limit_current = <1900>;

		/* 45w pwr on, 45w pwr off, 25w pwr on, 25w pwr off */
		battery,dchg_high_temp = <1000 1000 590 590>;
		battery,dchg_high_temp_recovery = <1000 1000 550 550>;
		battery,dchg_high_batt_temp = <1000 1000 1000 1000>; /* DISABLED */
		battery,dchg_high_batt_temp_recovery = <1000 1000 1000 1000>; /* DISABLED */
		battery,dchg_input_limit_current = <DCHG_ICL>;
		battery,dchg_charging_limit_current = <DCHG_FCC>;
		battery,dchg_dc_in_swelling;

		/* trig_step2_LCD_OFF, recov_step2_LCD_OFF, trig_step1_LCD_OFF, recov_step1_LCD_OFF,
		   trig_step2_LCD_ON, recov_step2_LCD_ON, trig_step1_LCD_ON, recov_step1_LCD_ON,
		   st1_icl, st1_fcc, st2_icl, st2_fcc */
		battery,temp_table_LRP_NORMAL = <
							400 390 390 380
							390 380 380 370
							1000 2400 1200 1800>;
		battery,temp_table_LRP_25W = <
							410 400 390 380
							400 390 380 370
							1700 3400 1100 2200>;

		battery,mix_high_temp = <420>;
		battery,mix_high_chg_temp = <500>;
		battery,mix_high_temp_recovery = <390>;

		battery,full_check_type = <SEC_BATTERY_FULLCHARGED_FG_CURRENT>;
		battery,full_check_type_2nd = <SEC_BATTERY_FULLCHARGED_FG_CURRENT>;

		battery,chg_float_voltage = <MAX_FV>;

		battery,swelling_high_rechg_voltage = <4050>;
		battery,swelling_low_rechg_voltage = <4270>;

		battery,max_charging_current = <MAX_FCC>;
		battery,max_charging_charge_power = <25000>; /* 25W */

		/* cycle, full_condition_soc, common_offset */
		battery,age_data_by_common_offset; /* Calculate Based on Common Offset */
		battery,age_data_cycle = <0 300 400 700 1001>;
		battery,age_data_full_condition_soc = <93 92 91 90 89>;
		battery,age_data_common_offset = <0 20 40 60 110>;

		/* direct step charging option */
		battery,dc_step_chg_type = <0xE9>;
		battery,dc_step_chg_charge_power = <22000>;
		battery,dc_step_chg_step = <3>;
		battery,dc_step_chg_cond_v_margin = <80>; /* mV */
		battery,dc_step_chg_cond_vol = <4130 4250 MAX_FV>; /* STEP_CHARGING_CONDITION_VOLTAGE */
		battery,dc_step_chg_cond_iin = <2290 1825 0>; /* STEP_CHARGING_CONDITION_INPUT_CURRENT */
		battery,dc_step_chg_iin_check_cnt = <3>;
		battery,dc_step_chg_cond_soc = <47 65 100>; /* STEP_CHARGING_CONDITION_SOC */
		battery,dc_step_chg_val_vfloat = <4130 4250 MAX_FV>; /* STEP_CHARGING_CONDITION_FLOAT_VOLTAGE */
		battery,dc_step_chg_val_iout = <5540 4580 3650>;

		battery,siop_scenarios = <20 0>;
		battery,siop_curr_type_num = <3>;
		/* nv, hv, fpdo */
		battery,siop_icl_20 = <1000 1000 1000>; /* 5W SIOP_DEFAULT 5W */
		battery,siop_fcc_20 = <SIOP_DEFAULT SIOP_DEFAULT SIOP_DEFAULT>;
		battery,siop_icl_0 = <1000 1000 1000>; /* 5W SIOP_DEFAULT 5W */
		battery,siop_fcc_0 = <SIOP_DEFAULT SIOP_DEFAULT SIOP_DEFAULT>;

		battery,standard_curr = <3690>;
		battery,expired_time = <9840>; /* 104 + 60 minutes */
		battery,recharging_expired_time = <5400>;
		battery,battery_full_capacity = <5000>;
		battery,cisd_max_voltage_thr = <5000>; /* batttery ovp dettection voltage */

		battery,inbat_ocv_type =  <SEC_BATTERY_OCV_VOLT_FROM_PMIC>;
		battery,slowcharging_usb_bootcomplete;
		battery,dynamic_cv_factor;
		battery,change_FV_after_full = <4420>;

		battery,ttf_hv_charge_current = <2085>;
		battery,ttf_dc25_charge_current = <3600>;
		battery,ttf_capacity = <3875>;
		battery,cv_data = <
				3590	830	1713
				3247	850	1599
				2720	870	1475
				2166	890	1319
				1701	910	1143
				1261	930	926
				940	950	676
				671	970	381
				554	990	93
				517	1000	0
					>;

		battery,boosting_voltage_aicl;
};

&sec_battery_cable {
		full_check_current_1st = <490>;
		full_check_current_2nd = <250>;

		current_group_4 {
			charging_current = <MAX_FCC>;
		};
		current_group_5 {
			charging_current = <MAX_FCC>;
		};
		current_group_6 {
			charging_current = <MAX_FCC>;
		};
		current_group_7 {
			charging_current = <MAX_FCC>;
		};
		current_group_10 {
			charging_current = <MAX_FCC>;
		};
};

/* revision devicetree for general */
#include "mt6877.a34x_eur_open.00.dtsi"

/ {
	compatible = "Samsung,A34 5G EUR OPEN","Mediatek,MT6877";
	dtbo-hw_rev = <0>;
	dtbo-hw_rev_end = <4>;
};
